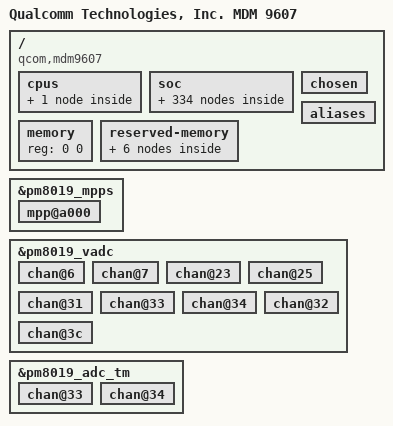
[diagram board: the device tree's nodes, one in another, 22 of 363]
/*
 * Copyright (c) 2015-2018, The Linux Foundation. All rights reserved.
 *
 * This program is free software; you can redistribute it and/or modify
 * it under the terms of the GNU General Public License version 2 and
 * only version 2 as published by the Free Software Foundation.
 *
 * This program is distributed in the hope that it will be useful,
 * but WITHOUT ANY WARRANTY; without even the implied warranty of
 * MERCHANTABILITY or FITNESS FOR A PARTICULAR PURPOSE.  See the
 * GNU General Public License for more details.
 */

// #include "skeleton.dtsi"
/*
 * Skeleton device tree; the bare minimum needed to boot; just include and
 * add a compatible value.  The bootloader will typically populate the memory
 * node.
 */

/ {
	#address-cells = <1>;
	#size-cells = <1>;
	cpus { };
	soc { };
	chosen { };
	aliases { };
	memory { device_type = "memory"; reg = <0 0>; };
};

#include <dt-bindings/clock/mdm-clocks-9607.h>
#include <dt-bindings/clock/msm-clocks-a7.h>
#include <dt-bindings/regulator/qcom,rpm-smd-regulator.h>
#include <dt-bindings/interrupt-controller/irq.h>

/ {
	model = "Qualcomm Technologies, Inc. MDM 9607";
	compatible = "qcom,mdm9607";
	qcom,msm-id = <290 0x10000>, <296 0x10000>, <297 0x10000>,
		      <298 0x10000>, <299 0x10000>;
	interrupt-parent = <&intc>;

	aliases {
		sdhc1 = &sdhc_1;/* SDC1 for SDIO slot */
		qpic_nand1 = &qnand_1;
	};

	reserved-memory {
		#address-cells = <1>;
		#size-cells = <1>;
		ranges;

		modem_adsp_mem: modem_adsp_region@0 {
			compatible = "removed-dma-pool";
			no-map-fixup;
			reg = <0x82c00000 0x5000000>;
		};

		cnss_debug_mem: cnss_debug_region@0 {
			compatible = "removed-dma-pool";
			no-map;
			reg = <0x82a00000 0x200000>;
		};

		external_image_mem: external_image_region@0 {
			compatible = "removed-dma-pool";
			no-map;
			reg = <0x87c00000 0x400000>;
		};

		tz_apps_mem: tz_apps_region@0 {
			compatible = "removed-dma-pool";
			no-map;
			reg = <0x88000000 0x500000>;
		};

		audio_mem: audio_region@0 {
			compatible = "shared-dma-pool";
			reusable;
			alignment = <0x400000>;
			size = <0x400000>;
		};

		qseecom_mem: qseecom_region@0 {
			compatible = "shared-dma-pool";
			reusable;
			alignment = <0x400000>;
			size = <0x0400000>;
			status = "ok";
		};
	};

	aliases {
		/* smdtty devices */
		smd7 = &smdtty_data1;
		smd8 = &smdtty_data4;
		smd9 = &smdtty_data2;
		smd10 = &smdtty_data3;
		/*smd11 = &smdtty_data11;*/ /*modified by max.tang@20160118. del Data11 from APP to be used by second USB AT port*/
		smd21 = &smdtty_data21;
		smd36 = &smdtty_loopback;
		/* spi device */
		/*Add spi3, spi5 node, gale 2018-3-14
		* according to AG35 Hardware Design, support three spi, spi_6 is actived,
		* and spi_3, spi_5 is inactived by default, user could enable it.
		*/
		spi3 = &spi_3;
		spi5 = &spi_5;
		//add by cullen
		spi6  = &spi_6;
		i2c2 = &i2c_2;
		i2c4 = &i2c_4;
		sdhc2 = &sdhc_2; /* SDC2 SD card slot */
	};

	cpus {
		#size-cells = <0>;
		#address-cells = <1>;

		CPU0: cpu@0 {
			device_type = "cpu";
			compatible = "arm,cortex-a7";
			reg = <0x0>;
			qcom,limits-info = <&mitigation_profile0>;
		};
	};
	soc: soc { };
};

// #include "mdm9607-ion.dtsi"
&soc {
	qcom,ion {
		compatible = "qcom,msm-ion";
		#address-cells = <1>;
		#size-cells = <0>;

		qcom,ion-heap@25 {
			reg = <25>;
			qcom,ion-heap-type = "SYSTEM";
		};

		qcom,ion-heap@28 { /* AUDIO HEAP */
			reg = <28>;
			memory-region = <&audio_mem>;
			qcom,ion-heap-type = "DMA";
		};

		qcom,ion-heap@27 { /* QSEECOM HEAP */
			reg = <27>;
			memory-region = <&qseecom_mem>;
			qcom,ion-heap-type = "DMA";
		};

	};
};

// #include "mdm9607-smp2p.dtsi"
&soc {
	qcom,smp2p-modem {
		compatible = "qcom,smp2p";
		reg = <0x0b011008 0x4>;
		qcom,remote-pid = <1>;
		qcom,irq-bitmask = <0x4000>;
		interrupts = <0 27 1>;
	};

	smp2pgpio_smp2p_15_in: qcom,smp2pgpio-smp2p-15-in {
		compatible = "qcom,smp2pgpio";
		qcom,entry-name = "smp2p";
		qcom,remote-pid = <15>;
		qcom,is-inbound;
		gpio-controller;
		#gpio-cells = <2>;
		interrupt-controller;
		#interrupt-cells = <2>;
	};

	qcom,smp2pgpio_test_smp2p_15_in {
		compatible = "qcom,smp2pgpio_test_smp2p_15_in";
		gpios = <&smp2pgpio_smp2p_15_in 0 0>;
	};

	smp2pgpio_smp2p_15_out: qcom,smp2pgpio-smp2p-15-out {
		compatible = "qcom,smp2pgpio";
		qcom,entry-name = "smp2p";
		qcom,remote-pid = <15>;
		gpio-controller;
		#gpio-cells = <2>;
		interrupt-controller;
		#interrupt-cells = <2>;
	};

	qcom,smp2pgpio_test_smp2p_15_out {
		compatible = "qcom,smp2pgpio_test_smp2p_15_out";
		gpios = <&smp2pgpio_smp2p_15_out 0 0>;
	};

	smp2pgpio_smp2p_1_in: qcom,smp2pgpio-smp2p-1-in {
		compatible = "qcom,smp2pgpio";
		qcom,entry-name = "smp2p";
		qcom,remote-pid = <1>;
		qcom,is-inbound;
		gpio-controller;
		#gpio-cells = <2>;
		interrupt-controller;
		#interrupt-cells = <2>;
	};

	qcom,smp2pgpio_test_smp2p_1_in {
		compatible = "qcom,smp2pgpio_test_smp2p_1_in";
		gpios = <&smp2pgpio_smp2p_1_in 0 0>;
	};

	smp2pgpio_smp2p_1_out: qcom,smp2pgpio-smp2p-1-out {
		compatible = "qcom,smp2pgpio";
		qcom,entry-name = "smp2p";
		qcom,remote-pid = <1>;
		gpio-controller;
		#gpio-cells = <2>;
		interrupt-controller;
		#interrupt-cells = <2>;
	};

	qcom,smp2pgpio_test_smp2p_1_out {
		compatible = "qcom,smp2pgpio_test_smp2p_1_out";
		gpios = <&smp2pgpio_smp2p_1_out 0 0>;
	};

	smp2pgpio_ssr_smp2p_1_in: qcom,smp2pgpio-ssr-smp2p-1-in {
			compatible = "qcom,smp2pgpio";
			qcom,entry-name = "slave-kernel";
			qcom,remote-pid = <1>;
			qcom,is-inbound;
			gpio-controller;
			#gpio-cells = <2>;
			interrupt-controller;
			#interrupt-cells = <2>;
	};

	smp2pgpio_ssr_smp2p_1_out: qcom,smp2pgpio-ssr-smp2p-1-out {
			compatible = "qcom,smp2pgpio";
			qcom,entry-name = "master-kernel";
			qcom,remote-pid = <1>;
			gpio-controller;
			#gpio-cells = <2>;
			interrupt-controller;
			#interrupt-cells = <2>;
	};
};


// #include "mdm9607-bus.dtsi"
#include <dt-bindings/msm/msm-bus-ids.h>
&soc {
	/* Version = 1 */
	ad_hoc_bus: ad-hoc-bus {
		compatible = "qcom,msm-bus-device";
		reg = <0x401000 0x58000>,
		      <0x500000 0x15080>;
		reg-names = "bimc-base", "pcnoc-base";

		/*Buses*/

		fab_bimc: fab-bimc {
			cell-id = <MSM_BUS_FAB_BIMC>;
			label = "fab-bimc";
			qcom,fab-dev;
			qcom,base-name = "bimc-base";
			qcom,bus-type = <2>;
			qcom,util-fact = <154>;
			clock-names = "bus_clk", "bus_a_clk";
			clocks = <&clock_gcc  clk_bimc_msmbus_clk>,
				<&clock_gcc  clk_bimc_msmbus_a_clk>;

			coresight-id = <203>;
			coresight-name = "coresight-bimc";
			coresight-nr-inports = <0>;
			coresight-outports = <0>;
			coresight-child-list = <&funnel_in0>;
			coresight-child-ports = <3>;
		};

		fab_pcnoc: fab-pcnoc {
			cell-id = <MSM_BUS_FAB_PERIPH_NOC>;
			label = "fab-pcnoc";
			qcom,fab-dev;
			qcom,base-name = "pcnoc-base";
			qcom,base-offset = <0x7000>;
			qcom,qos-off = <0x1000>;
			qcom,bus-type = <1>;
			clock-names = "bus_clk", "bus_a_clk";
			clocks = <&clock_gcc  clk_pcnoc_msmbus_clk>,
				<&clock_gcc  clk_pcnoc_msmbus_a_clk>;

			coresight-id = <201>;
			coresight-name = "coresight-pcnoc";
			coresight-nr-inports = <0>;
			coresight-outports = <0>;
			coresight-child-list = <&funnel_in2>;
			coresight-child-ports = <0>;
		};

		/*Masters*/

		mas_apps_proc: mas-apps-proc {
			cell-id = <MSM_BUS_MASTER_AMPSS_M0>;
			label = "mas-apps-proc";
			qcom,buswidth = <8>;
			qcom,agg-ports = <1>;
			qcom,ap-owned;
			qcom,qport = <0>;
			qcom,qos-mode = "fixed";
			qcom,connections = < &slv_bimc_pcnoc &slv_ebi>;
			qcom,prio-lvl = <0>;
			qcom,prio-rd = <0>;
			qcom,prio-wr = <0>;
			qcom,bus-dev = <&fab_bimc>;
			qcom,mas-rpm-id = <ICBID_MASTER_APPSS_PROC>;
		};

		mas_pcnoc_bimc_1: mas-pcnoc-bimc-1 {
			cell-id = <MSM_BUS_MASTER_PCNOC_BIMC_1>;
			label = "mas-pcnoc-bimc-1";
			qcom,buswidth = <8>;
			qcom,agg-ports = <1>;
			qcom,connections = <&slv_ebi>;
			qcom,bus-dev = <&fab_bimc>;
			qcom,mas-rpm-id = <ICBID_MASTER_PCNOC_BIMC_1>;
		};

		mas_tcu_0: mas-tcu-0 {
			cell-id = <MSM_BUS_MASTER_TCU_0>;
			label = "mas-tcu-0";
			qcom,buswidth = <8>;
			qcom,agg-ports = <1>;
			qcom,ap-owned;
			qcom,qport = <5>;
			qcom,qos-mode = "fixed";
			qcom,connections = <&slv_ebi>;
			qcom,prio-lvl = <2>;
			qcom,prio-rd = <2>;
			qcom,prio-wr = <2>;
			qcom,bus-dev = <&fab_bimc>;
			qcom,mas-rpm-id = <ICBID_MASTER_TCU_0>;
		};

		mas_qdss_bam: mas-qdss-bam {
			cell-id = <MSM_BUS_MASTER_QDSS_BAM>;
			label = "mas-qdss-bam";
			qcom,buswidth = <4>;
			qcom,agg-ports = <1>;
			qcom,connections = <&qdss_int>;
			qcom,bus-dev = <&fab_pcnoc>;
			qcom,mas-rpm-id = <ICBID_MASTER_QDSS_BAM>;
			qcom,blacklist = <&pcnoc_s_1 &pcnoc_s_2 &pcnoc_s_0
				 &pcnoc_s_4 &pcnoc_s_5 &pcnoc_s_3 &slv_tcu>;
		};

		mas_bimc_pcnoc: mas-bimc-pcnoc {
			cell-id = <MSM_BUS_MASTER_BIMC_PCNOC>;
			label = "mas-bimc-pcnoc";
			qcom,buswidth = <8>;
			qcom,agg-ports = <1>;
			qcom,connections = <&pcnoc_int_0
				 &pcnoc_int_2 &slv_cats_0>;
			qcom,bus-dev = <&fab_pcnoc>;
			qcom,mas-rpm-id = <ICBID_MASTER_BIMC_PCNOC>;
		};

		mas_qdss_etr: mas-qdss-etr {
			cell-id = <MSM_BUS_MASTER_QDSS_ETR>;
			label = "mas-qdss-etr";
			qcom,buswidth = <8>;
			qcom,agg-ports = <1>;
			qcom,connections = <&qdss_int>;
			qcom,bus-dev = <&fab_pcnoc>;
			qcom,mas-rpm-id = <ICBID_MASTER_QDSS_ETR>;
			qcom,blacklist = <&pcnoc_s_0 &pcnoc_s_2
					  &pcnoc_s_3 &pcnoc_s_4 &pcnoc_s_5
					  &slv_crypto_0_cfg &slv_message_ram
					  &slv_pdm &slv_prng &slv_qdss_stm
					  &slv_tcu>;
		};

		mas_audio: mas-audio {
			cell-id = <MSM_BUS_MASTER_AUDIO>;
			label = "mas-audio";
			qcom,buswidth = <4>;
			qcom,agg-ports = <1>;
			qcom,connections = <&pcnoc_m_0>;
			qcom,bus-dev = <&fab_pcnoc>;
			qcom,mas-rpm-id = <ICBID_MASTER_AUDIO>;
			qcom,blacklist = <&pcnoc_s_0 &pcnoc_s_1
					 &pcnoc_s_2 &pcnoc_s_3
					 &pcnoc_s_4 &pcnoc_s_5 &slv_tcu>;
		};

		mas_qpic: mas-qpic {
			cell-id = <MSM_BUS_MASTER_QPIC>;
			label = "mas-qpic";
			qcom,buswidth = <4>;
			qcom,agg-ports = <1>;
			qcom,connections = <&pcnoc_m_0>;
			qcom,bus-dev = <&fab_pcnoc>;
			qcom,mas-rpm-id = <ICBID_MASTER_QPIC>;
			qcom,blacklist = <&pcnoc_s_0 &pcnoc_s_2
					  &pcnoc_s_3 &pcnoc_s_4
					  &pcnoc_s_5 &slv_tcu
					  &slv_crypto_0_cfg &slv_pdm
					  &slv_prng &slv_usb2 >;
		};

		mas_hsic: mas-hsic {
			cell-id = <MSM_BUS_MASTER_USB_HSIC>;
			label = "mas-hsic";
			qcom,buswidth = <4>;
			qcom,agg-ports = <1>;
			qcom,connections = <&pcnoc_m_0>;
			qcom,bus-dev = <&fab_pcnoc>;
			qcom,mas-rpm-id = <ICBID_MASTER_USB_HSIC>;
		};

		mas_blsp_1: mas-blsp-1 {
			cell-id = <MSM_BUS_MASTER_BLSP_1>;
			label = "mas-blsp-1";
			qcom,buswidth = <4>;
			qcom,agg-ports = <1>;
			qcom,connections = <&pcnoc_m_1>;
			qcom,bus-dev = <&fab_pcnoc>;
			qcom,mas-rpm-id = <ICBID_MASTER_BLSP_1>;
			qcom,blacklist = <&pcnoc_s_0 &pcnoc_s_1
					 &pcnoc_s_2 &pcnoc_s_3
					 &pcnoc_s_4 &pcnoc_s_5 &slv_tcu >;
		};

		mas_usb_hs1: mas-usb-hs1 {
			cell-id = <MSM_BUS_MASTER_USB_HS>;
			label = "mas-usb-hs1";
			qcom,buswidth = <4>;
			qcom,agg-ports = <1>;
			qcom,connections = <&pcnoc_m_1>;
			qcom,bus-dev = <&fab_pcnoc>;
			qcom,mas-rpm-id = <ICBID_MASTER_USB_HS1>;
			qcom,blacklist = <&pcnoc_s_0 &pcnoc_s_2 &pcnoc_s_4
					 &pcnoc_s_5 &slv_tcu
					 &slv_crypto_0_cfg
					 &slv_pdm &slv_prng &slv_usb2
					 &slv_usb_phy> ;
		};

		mas_crypto: mas-crypto {
			cell-id = <MSM_BUS_MASTER_CRYPTO>;
			label = "mas-crypto";
			qcom,buswidth = <8>;
			qcom,agg-ports = <1>;
			qcom,ap-owned;
			qcom,qport = <0>;
			qcom,qos-mode = "fixed";
			qcom,connections = <&pcnoc_int_3>;
			qcom,prio1 = <2>;
			qcom,prio0 = <2>;
			qcom,bus-dev = <&fab_pcnoc>;
			qcom,mas-rpm-id = <ICBID_MASTER_CRYPTO>;
			qcom,blacklist = <&pcnoc_s_0 &pcnoc_s_2 &pcnoc_s_3
					  &pcnoc_s_4 &pcnoc_s_5 &slv_tcu
					  &slv_crypto_0_cfg &slv_pdm
					  &slv_usb2 &slv_prng>;
		};

		mas_sdcc_1: mas-sdcc-1 {
			cell-id = <MSM_BUS_MASTER_SDCC_1>;
			label = "mas-sdcc-1";
			qcom,buswidth = <8>;
			qcom,agg-ports = <1>;
			qcom,connections = <&pcnoc_int_3>;
			qcom,bus-dev = <&fab_pcnoc>;
			qcom,mas-rpm-id = <ICBID_MASTER_SDCC_1>;
			qcom,blacklist = <&pcnoc_s_0 &pcnoc_s_2 &pcnoc_s_3
					 &pcnoc_s_4 &pcnoc_s_5 &slv_tcu
					 &slv_crypto_0_cfg &slv_pdm
					 &slv_usb2 &slv_prng>;
		};

		mas_sdcc_2: mas-sdcc-2 {
			cell-id = <MSM_BUS_MASTER_SDCC_2>;
			label = "mas-sdcc-2";
			qcom,buswidth = <8>;
			qcom,agg-ports = <1>;
			qcom,connections = <&pcnoc_int_3>;
			qcom,bus-dev = <&fab_pcnoc>;
			qcom,mas-rpm-id = <ICBID_MASTER_SDCC_2>;
			qcom,blacklist = <&pcnoc_s_0 &pcnoc_s_2 &pcnoc_s_3
					 &pcnoc_s_4 &pcnoc_s_5 &slv_tcu
					 &slv_crypto_0_cfg &slv_pdm
					 &slv_usb2 &slv_prng>;
		};

		mas_xi_usb_hs1: mas-xi-usb-hs1 {
			cell-id = <MSM_BUS_MASTER_XM_USB_HS1>;
			label = "mas-xi-usb-hs1";
			qcom,buswidth = <8>;
			qcom,agg-ports = <1>;
			qcom,connections = <&slv_pcnoc_bimc_1 &pcnoc_int_2>;
			qcom,bus-dev = <&fab_pcnoc>;
			qcom,mas-rpm-id = <ICBID_MASTER_XI_USB_HS1>;
			qcom,blacklist = <&pcnoc_s_0 &pcnoc_s_2 &pcnoc_s_4
					 &pcnoc_s_5 &slv_tcu &slv_crypto_0_cfg
					 &slv_pdm &slv_usb2 &slv_prng
					 &slv_usb_phy>;
		};

		mas_xi_hsic: mas-xi-hsic {
			cell-id = <MSM_BUS_MASTER_XI_USB_HSIC>;
			label = "mas-xi-hsic";
			qcom,buswidth = <8>;
			qcom,agg-ports = <1>;
			qcom,connections = <&slv_pcnoc_bimc_1 &pcnoc_int_2>;
			qcom,bus-dev = <&fab_pcnoc>;
			qcom,mas-rpm-id = <ICBID_MASTER_XI_HSIC>;
			qcom,blacklist = <&pcnoc_s_0 &pcnoc_s_2
					 &pcnoc_s_3 &pcnoc_s_4 &pcnoc_s_5
					 &slv_tcu &slv_crypto_0_cfg
					 &slv_pdm &slv_usb2 &slv_prng>;
		};

		mas_sgmii: mas-sgmii {
			cell-id = <MSM_BUS_MASTER_SGMII>;
			label = "mas-sgmii";
			qcom,buswidth = <8>;
			qcom,agg-ports = <1>;
			qcom,ap-owned;
			qcom,qport = <10>;
			qcom,qos-mode = "fixed";
			qcom,connections = <&slv_pcnoc_bimc_1 &pcnoc_int_2>;
			qcom,prio1 = <1>;
			qcom,prio0 = <1>;
			qcom,bus-dev = <&fab_pcnoc>;
			qcom,mas-rpm-id = <ICBID_MASTER_SGMII>;
			qcom,blacklist = <&pcnoc_s_0 &pcnoc_s_2 &pcnoc_s_3
					 &pcnoc_s_4 &pcnoc_s_5 &slv_tcu
					 &slv_crypto_0_cfg &slv_pdm
					 &slv_usb2 &slv_prng>;
		};

		/*Internal nodes*/

		pcnoc_m_0: pcnoc-m-0 {
			cell-id = <MSM_BUS_PNOC_M_0>;
			label = "pcnoc-m-0";
			qcom,buswidth = <4>;
			qcom,agg-ports = <1>;
			qcom,connections = <&slv_pcnoc_bimc_1 &pcnoc_int_2>;
			qcom,bus-dev = <&fab_pcnoc>;
			qcom,mas-rpm-id = <ICBID_MASTER_PCNOC_M_0>;
			qcom,slv-rpm-id = <ICBID_SLAVE_PCNOC_M_0>;
		};

		pcnoc_m_1: pcnoc-m-1 {
			cell-id = <MSM_BUS_PNOC_M_1>;
			label = "pcnoc-m-1";
			qcom,buswidth = <4>;
			qcom,agg-ports = <1>;
			qcom,connections = <&slv_pcnoc_bimc_1 &pcnoc_int_2>;
			qcom,bus-dev = <&fab_pcnoc>;
			qcom,mas-rpm-id = <ICBID_MASTER_PCNOC_M_1>;
			qcom,slv-rpm-id = <ICBID_SLAVE_PCNOC_M_1>;
		};

		qdss_int: qdss-int {
			cell-id = <MSM_BUS_SNOC_QDSS_INT>;
			label = "qdss-int";
			qcom,buswidth = <8>;
			qcom,agg-ports = <1>;
			qcom,connections = <&pcnoc_int_0 &slv_pcnoc_bimc_1>;
			qcom,bus-dev = <&fab_pcnoc>;
			qcom,mas-rpm-id = <ICBID_MASTER_QDSS_INT>;
			qcom,slv-rpm-id = <ICBID_SLAVE_QDSS_INT>;
		};

		pcnoc_int_0: pcnoc-int-0 {
			cell-id = <MSM_BUS_PNOC_INT_0>;
			label = "pcnoc-int-0";
			qcom,buswidth = <8>;
			qcom,agg-ports = <1>;
			qcom,ap-owned;
			qcom,connections = <&slv_imem &slv_qdss_stm>;
			qcom,bus-dev = <&fab_pcnoc>;
			qcom,mas-rpm-id = <ICBID_MASTER_PCNOC_INT_0>;
			qcom,slv-rpm-id = <ICBID_SLAVE_PCNOC_INT_0>;
		};

		pcnoc_int_2: pcnoc-int-2 {
			cell-id = <MSM_BUS_PNOC_INT_2>;
			label = "pcnoc-int-2";
			qcom,buswidth = <8>;
			qcom,agg-ports = <1>;
			qcom,connections = <&pcnoc_s_1 &pcnoc_s_2
					 &pcnoc_s_0 &pcnoc_s_4
					 &pcnoc_s_5 &pcnoc_s_3
					 &slv_tcu >;
			qcom,bus-dev = <&fab_pcnoc>;
			qcom,mas-rpm-id = <ICBID_MASTER_PCNOC_INT_2>;
			qcom,slv-rpm-id = <ICBID_SLAVE_PCNOC_INT_2>;
		};

		pcnoc_int_3: pcnoc-int-3 {
			cell-id = <MSM_BUS_PNOC_INT_3>;
			label = "pcnoc-int-3";
			qcom,buswidth = <8>;
			qcom,agg-ports = <1>;
			qcom,connections = <&slv_pcnoc_bimc_1 &pcnoc_int_2>;
			qcom,bus-dev = <&fab_pcnoc>;
			qcom,mas-rpm-id = <ICBID_MASTER_PCNOC_INT_3>;
			qcom,slv-rpm-id = <ICBID_SLAVE_PCNOC_INT_3>;
		};

		pcnoc_s_0: pcnoc-s-0 {
			cell-id = <MSM_BUS_PNOC_SLV_0>;
			label = "pcnoc-s-0";
			qcom,buswidth = <4>;
			qcom,agg-ports = <1>;
			qcom,connections = <&slv_tcsr &slv_sdcc_1 &slv_blsp_1
				 &slv_sgmii>;
			qcom,bus-dev = <&fab_pcnoc>;
			qcom,mas-rpm-id = <ICBID_MASTER_PCNOC_S_0>;
			qcom,slv-rpm-id = <ICBID_SLAVE_PCNOC_S_0>;
		};

		pcnoc_s_1: pcnoc-s-1 {
			cell-id = <MSM_BUS_PNOC_SLV_1>;
			label = "pcnoc-s-1";
			qcom,buswidth = <4>;
			qcom,agg-ports = <1>;
			qcom,connections = <&slv_usb2 &slv_crypto_0_cfg
					 &slv_prng &slv_pdm
					 &slv_message_ram>;
			qcom,bus-dev = <&fab_pcnoc>;
			qcom,mas-rpm-id = <ICBID_MASTER_PCNOC_S_1>;
			qcom,slv-rpm-id = <ICBID_SLAVE_PCNOC_S_1>;
		};

		pcnoc_s_2: pcnoc-s-2 {
			cell-id = <MSM_BUS_PNOC_SLV_2>;
			label = "pcnoc-s-2";
			qcom,buswidth = <4>;
			qcom,agg-ports = <1>;
			qcom,connections = <&slv_hsic &slv_sdcc_2 &slv_audio>;
			qcom,bus-dev = <&fab_pcnoc>;
			qcom,mas-rpm-id = <ICBID_MASTER_PCNOC_S_2>;
			qcom,slv-rpm-id = <ICBID_SLAVE_PCNOC_S_2>;
		};

		pcnoc_s_3: pcnoc-s-3 {
			cell-id = <MSM_BUS_PNOC_SLV_3>;
			label = "pcnoc-s-3";
			qcom,buswidth = <4>;
			qcom,agg-ports = <1>;
			qcom,ap-owned;
			qcom,connections = <&slv_usb_phy>;
			qcom,bus-dev = <&fab_pcnoc>;
			qcom,mas-rpm-id = <ICBID_MASTER_PCNOC_S_3>;
			qcom,slv-rpm-id = <ICBID_SLAVE_PCNOC_S_3>;
		};

		pcnoc_s_4: pcnoc-s-4 {
			cell-id = <MSM_BUS_PNOC_SLV_4>;
			label = "pcnoc-s-4";
			qcom,buswidth = <4>;
			qcom,agg-ports = <1>;
			qcom,connections = <&slv_imem_cfg &slv_pmic_arb>;
			qcom,bus-dev = <&fab_pcnoc>;
			qcom,mas-rpm-id = <ICBID_MASTER_PCNOC_S_4>;
			qcom,slv-rpm-id = <ICBID_SLAVE_PCNOC_S_4>;
		};

		pcnoc_s_5: pcnoc-s-5 {
			cell-id = <MSM_BUS_PNOC_SLV_5>;
			label = "pcnoc-s-5";
			qcom,buswidth = <4>;
			qcom,agg-ports = <1>;
			qcom,connections = <&slv_tlmm>;
			qcom,bus-dev = <&fab_pcnoc>;
			qcom,mas-rpm-id = <ICBID_MASTER_PCNOC_S_5>;
			qcom,slv-rpm-id = <ICBID_SLAVE_PCNOC_S_5>;
		};

		/*Slaves*/

		slv_ebi:slv-ebi {
			cell-id = <MSM_BUS_SLAVE_EBI_CH0>;
			label = "slv-ebi";
			qcom,buswidth = <8>;
			qcom,agg-ports = <1>;
			qcom,bus-dev = <&fab_bimc>;
			qcom,slv-rpm-id = <ICBID_SLAVE_EBI1>;
		};

		slv_bimc_pcnoc:slv-bimc-pcnoc {
			cell-id = <MSM_BUS_SLAVE_BIMC_PCNOC>;
			label = "slv-bimc-pcnoc";
			qcom,buswidth = <8>;
			qcom,agg-ports = <1>;
			qcom,bus-dev = <&fab_bimc>;
			qcom,connections = <&mas_bimc_pcnoc>;
			qcom,slv-rpm-id = <ICBID_SLAVE_BIMC_PCNOC>;
		};

		slv_pcnoc_bimc_1:slv-pcnoc-bimc-1 {
			cell-id = <MSM_BUS_SLAVE_PCNOC_BIMC_1>;
			label = "slv-pcnoc-bimc-1";
			qcom,buswidth = <8>;
			qcom,agg-ports = <1>;
			qcom,bus-dev = <&fab_pcnoc>;
			qcom,connections = <&mas_pcnoc_bimc_1>;
			qcom,slv-rpm-id = <ICBID_SLAVE_PCNOC_BIMC_1>;
		};

		slv_qdss_stm:slv-qdss-stm {
			cell-id = <MSM_BUS_SLAVE_QDSS_STM>;
			label = "slv-qdss-stm";
			qcom,buswidth = <4>;
			qcom,agg-ports = <1>;
			qcom,ap-owned;
			qcom,bus-dev = <&fab_pcnoc>;
			qcom,slv-rpm-id = <ICBID_SLAVE_QDSS_STM>;
		};

		slv_cats_0:slv-cats-0 {
			cell-id = <MSM_BUS_SLAVE_CATS_128>;
			label = "slv-cats-0";
			qcom,buswidth = <8>;
			qcom,agg-ports = <1>;
			qcom,ap-owned;
			qcom,bus-dev = <&fab_pcnoc>;
			qcom,slv-rpm-id = <ICBID_SLAVE_CATS_0>;
		};

		slv_imem:slv-imem {
			cell-id = <MSM_BUS_SLAVE_SYSTEM_IMEM>;
			label = "slv-imem";
			qcom,buswidth = <8>;
			qcom,agg-ports = <1>;
			qcom,ap-owned;
			qcom,bus-dev = <&fab_pcnoc>;
			qcom,slv-rpm-id = <ICBID_SLAVE_IMEM>;
		};

		slv_tcsr:slv-tcsr {
			cell-id = <MSM_BUS_SLAVE_TCSR>;
			label = "slv-tcsr";
			qcom,buswidth = <4>;
			qcom,agg-ports = <1>;
			qcom,bus-dev = <&fab_pcnoc>;
			qcom,slv-rpm-id = <ICBID_SLAVE_TCSR>;
		};

		slv_sdcc_1:slv-sdcc-1 {
			cell-id = <MSM_BUS_SLAVE_SDCC_1>;
			label = "slv-sdcc-1";
			qcom,buswidth = <4>;
			qcom,agg-ports = <1>;
			qcom,bus-dev = <&fab_pcnoc>;
			qcom,slv-rpm-id = <ICBID_SLAVE_SDCC_1>;
		};

		slv_blsp_1:slv-blsp-1 {
			cell-id = <MSM_BUS_SLAVE_BLSP_1>;
			label = "slv-blsp-1";
			qcom,buswidth = <4>;
			qcom,agg-ports = <1>;
			qcom,bus-dev = <&fab_pcnoc>;
			qcom,slv-rpm-id = <ICBID_SLAVE_BLSP_1>;
		};

		slv_sgmii:slv-sgmii {
			cell-id = <MSM_BUS_SLAVE_SGMII>;
			label = "slv-sgmii";
			qcom,buswidth = <4>;
			qcom,agg-ports = <1>;
			qcom,ap-owned;
			qcom,bus-dev = <&fab_pcnoc>;
			qcom,slv-rpm-id = <ICBID_SLAVE_SGMII>;
		};

		slv_crypto_0_cfg:slv-crypto-0-cfg {
			cell-id = <MSM_BUS_SLAVE_CRYPTO_0_CFG>;
			label = "slv-crypto-0-cfg";
			qcom,buswidth = <4>;
			qcom,agg-ports = <1>;
			qcom,ap-owned;
			qcom,bus-dev = <&fab_pcnoc>;
			qcom,slv-rpm-id = <ICBID_SLAVE_CRYPTO_0_CFG>;
		};

		slv_message_ram:slv-message-ram {
			cell-id = <MSM_BUS_SLAVE_MESSAGE_RAM>;
			label = "slv-message-ram";
			qcom,buswidth = <4>;
			qcom,agg-ports = <1>;
			qcom,bus-dev = <&fab_pcnoc>;
			qcom,slv-rpm-id = <ICBID_SLAVE_MESSAGE_RAM>;
		};

		slv_pdm:slv-pdm {
			cell-id = <MSM_BUS_SLAVE_PDM>;
			label = "slv-pdm";
			qcom,buswidth = <4>;
			qcom,agg-ports = <1>;
			qcom,bus-dev = <&fab_pcnoc>;
			qcom,slv-rpm-id = <ICBID_SLAVE_PDM>;
		};

		slv_prng:slv-prng {
			cell-id = <MSM_BUS_SLAVE_PRNG>;
			label = "slv-prng";
			qcom,buswidth = <4>;
			qcom,agg-ports = <1>;
			qcom,bus-dev = <&fab_pcnoc>;
			qcom,slv-rpm-id = <ICBID_SLAVE_PRNG>;
		};

		slv_usb2:slv-usb2 {
			cell-id = <MSM_BUS_SLAVE_USB_HS>;
			label = "slv-usb2";
			qcom,buswidth = <4>;
			qcom,agg-ports = <1>;
			qcom,ap-owned;
			qcom,bus-dev = <&fab_pcnoc>;
			qcom,slv-rpm-id = <ICBID_SLAVE_USB_HS>;
		};

		slv_sdcc_2:slv-sdcc-2 {
			cell-id = <MSM_BUS_SLAVE_SDCC_2>;
			label = "slv-sdcc-2";
			qcom,buswidth = <4>;
			qcom,agg-ports = <1>;
			qcom,bus-dev = <&fab_pcnoc>;
			qcom,slv-rpm-id = <ICBID_SLAVE_SDCC_2>;
		};

		slv_audio:slv-audio {
			cell-id = <MSM_BUS_SLAVE_AUDIO>;
			label = "slv-audio";
			qcom,buswidth = <4>;
			qcom,agg-ports = <1>;
			qcom,bus-dev = <&fab_pcnoc>;
			qcom,slv-rpm-id = <ICBID_SLAVE_AUDIO>;
		};

		slv_hsic:slv-hsic {
			cell-id = <MSM_BUS_SLAVE_USB_HSIC>;
			label = "slv-hsic";
			qcom,buswidth = <4>;
			qcom,agg-ports = <1>;
			qcom,bus-dev = <&fab_pcnoc>;
			qcom,slv-rpm-id = <ICBID_SLAVE_USB_HSIC>;
		};

		slv_usb_phy:slv-usb-phy {
			cell-id = <MSM_BUS_SLAVE_USB_PHYS_CFG>;
			label = "slv-usb-phy";
			qcom,buswidth = <4>;
			qcom,agg-ports = <1>;
			qcom,ap-owned;
			qcom,bus-dev = <&fab_pcnoc>;
			qcom,slv-rpm-id = <ICBID_SLAVE_USB_PHY_CFG>;
		};

		slv_tlmm:slv-tlmm {
			cell-id = <MSM_BUS_SLAVE_TLMM>;
			label = "slv-tlmm";
			qcom,buswidth = <4>;
			qcom,agg-ports = <1>;
			qcom,bus-dev = <&fab_pcnoc>;
			qcom,slv-rpm-id = <ICBID_SLAVE_TLMM>;
		};

		slv_imem_cfg:slv-imem-cfg {
			cell-id = <MSM_BUS_SLAVE_IMEM_CFG>;
			label = "slv-imem-cfg";
			qcom,buswidth = <4>;
			qcom,agg-ports = <1>;
			qcom,ap-owned;
			qcom,bus-dev = <&fab_pcnoc>;
			qcom,slv-rpm-id = <ICBID_SLAVE_IMEM_CFG>;
		};

		slv_pmic_arb:slv-pmic-arb {
			cell-id = <MSM_BUS_SLAVE_PMIC_ARB>;
			label = "slv-pmic-arb";
			qcom,buswidth = <4>;
			qcom,agg-ports = <1>;
			qcom,bus-dev = <&fab_pcnoc>;
			qcom,slv-rpm-id = <ICBID_SLAVE_PMIC_ARB>;
		};

		slv_tcu:slv-tcu {
			cell-id = <MSM_BUS_SLAVE_TCU>;
			label = "slv-tcu";
			qcom,buswidth = <8>;
			qcom,agg-ports = <1>;
			qcom,ap-owned;
			qcom,bus-dev = <&fab_pcnoc>;
			qcom,slv-rpm-id = <ICBID_SLAVE_TCU>;
		};

		slv_qipc {
			cell-id = <MSM_BUS_SLAVE_QPIC>;
			label = "slv-qpic";
			qcom,buswidth = <4>;
			qcom,agg-ports = <1>;
			qcom,bus-dev = <&fab_pcnoc>;
			qcom,slv-rpm-id = <ICBID_SLAVE_QPIC>;

		};
	};
};

// #include "mdm9607-coresight.dtsi"

&soc {
	tmc_etr: tmc@6026000 {
		compatible = "arm,coresight-tmc";
		reg = <0x6026000 0x1000>,
		      <0x6084000 0x15000>;
		reg-names = "tmc-base", "bam-base";
		interrupts = <0 166 0>;
		interrupt-names = "byte-cntr-irq";

		qcom,memory-size = <0x100000>;
		qcom,sg-enable;

		coresight-id = <0>;
		coresight-name = "coresight-tmc-etr";
		coresight-nr-inports = <1>;
		coresight-ctis = <&cti0 &cti8>;

		clocks = <&clock_gcc clk_qdss_clk>,
			 <&clock_gcc clk_qdss_a_clk>;
		clock-names = "core_clk", "core_a_clk";
	};

	tpiu: tpiu@6020000 {
		compatible = "arm,coresight-tpiu";
		reg = <0x6020000 0x1000>,
		      <0x1100000 0xb0000>;
		reg-names = "tpiu-base", "nidnt-base";

		coresight-id = <1>;
		coresight-name = "coresight-tpiu";
		coresight-nr-inports = <1>;

		pinctrl-names = "sdcard", "trace", "swduart",
				"swdtrc", "jtag", "spmi";
		/* NIDnT */
		pinctrl-0 = <&qdsd_clk_sdcard &qdsd_cmd_sdcard
			     &qdsd_data0_sdcard &qdsd_data1_sdcard
			     &qdsd_data2_sdcard &qdsd_data3_sdcard>;
		pinctrl-1 = <&qdsd_clk_trace &qdsd_cmd_trace
			     &qdsd_data0_trace &qdsd_data1_trace
			     &qdsd_data2_trace &qdsd_data3_trace>;
		pinctrl-2 = <&qdsd_cmd_swduart &qdsd_data0_swduart
			     &qdsd_data1_swduart &qdsd_data2_swduart
			     &qdsd_data3_swduart>;
		pinctrl-3 = <&qdsd_clk_swdtrc &qdsd_cmd_swdtrc
			     &qdsd_data0_swdtrc &qdsd_data1_swdtrc
			     &qdsd_data2_swdtrc &qdsd_data3_swdtrc>;
		pinctrl-4 = <&qdsd_cmd_jtag &qdsd_data0_jtag
			     &qdsd_data1_jtag &qdsd_data2_jtag
			     &qdsd_data3_jtag>;
		pinctrl-5 = <&qdsd_clk_spmi &qdsd_cmd_spmi
			     &qdsd_data0_spmi &qdsd_data3_spmi>;

		qcom,nidnthw;
		qcom,nidnt-swduart;
		qcom,nidnt-swdtrc;
		qcom,nidnt-jtag;
		qcom,nidnt-spmi;
		nidnt-gpio = <&tlmm_pinmux 26 0>;
		nidnt-gpio-polarity = <1>;

		interrupts = <0 82 0>;
		interrupt-names = "nidnt-irq";

		vdd-supply = <&sdcard_ext_vreg>;
		qcom,vdd-voltage-level = <2850000 2850000>;
		qcom,vdd-current-level = <15 400000>;

		vdd-io-supply = <&mdm9607_l13>;
		qcom,vdd-io-voltage-level = <1800000 2950000>;
		qcom,vdd-io-current-level = <200 300000>;

		clocks = <&clock_gcc clk_qdss_clk>,
			 <&clock_gcc clk_qdss_a_clk>;
		clock-names = "core_clk", "core_a_clk";
	};

	replicator: replicator@6024000 {
		compatible = "qcom,coresight-replicator";
		reg = <0x6024000 0x1000>;
		reg-names = "replicator-base";

		coresight-id = <2>;
		coresight-name = "coresight-replicator";
		coresight-nr-inports = <1>;
		coresight-outports = <0 1>;
		coresight-child-list = <&tmc_etr &tpiu>;
		coresight-child-ports = <0 0>;

		clocks = <&clock_gcc clk_qdss_clk>,
			 <&clock_gcc clk_qdss_a_clk>;
		clock-names = "core_clk", "core_a_clk";
	};

	tmc_etf: tmc@6025000 {
		compatible = "arm,coresight-tmc";
		reg = <0x6025000 0x1000>;
		reg-names = "tmc-base";

		coresight-id = <3>;
		coresight-name = "coresight-tmc-etf";
		coresight-nr-inports = <1>;
		coresight-outports = <0>;
		coresight-child-list = <&replicator>;
		coresight-child-ports = <0>;
		coresight-default-sink;
		coresight-ctis = <&cti0 &cti8>;

		clocks = <&clock_gcc clk_qdss_clk>,
			 <&clock_gcc clk_qdss_a_clk>;
		clock-names = "core_clk", "core_a_clk";
	};

	funnel_in0: funnel@6021000 {
		compatible = "arm,coresight-funnel";
		reg = <0x6021000 0x1000>;
		reg-names = "funnel-base";

		coresight-id = <4>;
		coresight-name = "coresight-funnel-in0";
		coresight-nr-inports = <8>;
		coresight-outports = <0>;
		coresight-child-list = <&tmc_etf>;
		coresight-child-ports = <0>;

		clocks = <&clock_gcc clk_qdss_clk>,
			 <&clock_gcc clk_qdss_a_clk>;
		clock-names = "core_clk", "core_a_clk";
	};

	funnel_in2: funnel@6068000 {
		compatible = "arm,coresight-funnel";
		reg = <0x6068000 0x1000>;
		reg-names = "funnel-base";

		coresight-id = <5>;
		coresight-name = "coresight-funnel-in2";
		coresight-nr-inports = <2>;
		coresight-outports = <0>;
		coresight-child-list = <&funnel_in0>;
		coresight-child-ports = <6>;

		clocks = <&clock_gcc clk_qdss_clk>,
			 <&clock_gcc clk_qdss_a_clk>;
		clock-names = "core_clk", "core_a_clk";
	};

	cti0: cti@6010000 {
		compatible = "arm,coresight-cti";
		reg = <0x6010000 0x1000>;
		reg-names = "cti-base";

		coresight-id = <6>;
		coresight-name = "coresight-cti0";
		coresight-nr-inports = <0>;

		clocks = <&clock_gcc clk_qdss_clk>,
			 <&clock_gcc clk_qdss_a_clk>;
		clock-names = "core_clk", "core_a_clk";
	};

	cti1: cti@6011000 {
		compatible = "arm,coresight-cti";
		reg = <0x6011000 0x1000>;
		reg-names = "cti-base";

		coresight-id = <7>;
		coresight-name = "coresight-cti1";
		coresight-nr-inports = <0>;

		clocks = <&clock_gcc clk_qdss_clk>,
			 <&clock_gcc clk_qdss_a_clk>;
		clock-names = "core_clk", "core_a_clk";
	};

	cti2: cti@6012000 {
		compatible = "arm,coresight-cti";
		reg = <0x6012000 0x1000>;
		reg-names = "cti-base";

		coresight-id = <8>;
		coresight-name = "coresight-cti2";
		coresight-nr-inports = <0>;

		clocks = <&clock_gcc clk_qdss_clk>,
			 <&clock_gcc clk_qdss_a_clk>;
		clock-names = "core_clk", "core_a_clk";
	};

	cti3: cti@6013000 {
		compatible = "arm,coresight-cti";
		reg = <0x6013000 0x1000>;
		reg-names = "cti-base";

		coresight-id = <9>;
		coresight-name = "coresight-cti3";
		coresight-nr-inports = <0>;

		clocks = <&clock_gcc clk_qdss_clk>,
			 <&clock_gcc clk_qdss_a_clk>;
		clock-names = "core_clk", "core_a_clk";
	};

	cti4: cti@6014000 {
		compatible = "arm,coresight-cti";
		reg = <0x6014000 0x1000>;
		reg-names = "cti-base";

		coresight-id = <10>;
		coresight-name = "coresight-cti4";
		coresight-nr-inports = <0>;

		clocks = <&clock_gcc clk_qdss_clk>,
			 <&clock_gcc clk_qdss_a_clk>;
		clock-names = "core_clk", "core_a_clk";
	};

	cti5: cti@6015000 {
		compatible = "arm,coresight-cti";
		reg = <0x6015000 0x1000>;
		reg-names = "cti-base";

		coresight-id = <11>;
		coresight-name = "coresight-cti5";
		coresight-nr-inports = <0>;

		clocks = <&clock_gcc clk_qdss_clk>,
			 <&clock_gcc clk_qdss_a_clk>;
		clock-names = "core_clk", "core_a_clk";
	};

	cti6: cti@6016000 {
		compatible = "arm,coresight-cti";
		reg = <0x6016000 0x1000>;
		reg-names = "cti-base";

		coresight-id = <12>;
		coresight-name = "coresight-cti6";
		coresight-nr-inports = <0>;

		clocks = <&clock_gcc clk_qdss_clk>,
			 <&clock_gcc clk_qdss_a_clk>;
		clock-names = "core_clk", "core_a_clk";
	};

	cti7: cti@6017000 {
		compatible = "arm,coresight-cti";
		reg = <0x6017000 0x1000>;
		reg-names = "cti-base";

		coresight-id = <13>;
		coresight-name = "coresight-cti7";
		coresight-nr-inports = <0>;

		clocks = <&clock_gcc clk_qdss_clk>,
			 <&clock_gcc clk_qdss_a_clk>;
		clock-names = "core_clk", "core_a_clk";
	};

	cti8: cti@6018000 {
		compatible = "arm,coresight-cti";
		reg = <0x6018000 0x1000>;
		reg-names = "cti-base";

		coresight-id = <14>;
		coresight-name = "coresight-cti8";
		coresight-nr-inports = <0>;

		clocks = <&clock_gcc clk_qdss_clk>,
			 <&clock_gcc clk_qdss_a_clk>;
		clock-names = "core_clk", "core_a_clk";
	};

	cti_cpu0: cti@6043000 {
		compatible = "arm,coresight-cti";
		reg = <0x6043000 0x1000>;
		reg-names = "cti-base";

		coresight-id = <15>;
		coresight-name = "coresight-cti-cpu0";
		coresight-nr-inports = <0>;
		coresight-cti-cpu = <&CPU0>;

		qcom,cti-save;

		clocks = <&clock_gcc clk_qdss_clk>,
			 <&clock_gcc clk_qdss_a_clk>;
		clock-names = "core_clk", "core_a_clk";
	};

	cti_rpm_cpu0: cti@603c000 {
		compatible = "arm,coresight-cti";
		reg = <0x603c000 0x1000>;
		reg-names = "cti-base";

		coresight-id = <16>;
		coresight-name = "coresight-cti-rpm-cpu0";
		coresight-nr-inports = <0>;

		clocks = <&clock_gcc clk_qdss_clk>,
			 <&clock_gcc clk_qdss_a_clk>;
		clock-names = "core_clk", "core_a_clk";
	};

	cti_modem_cpu0: cti@6038000 {
		compatible = "arm,coresight-cti";
		reg = <0x6038000 0x1000>;
		reg-names = "cti-base";

		coresight-id = <17>;
		coresight-name = "coresight-cti-modem-cpu0";
		coresight-nr-inports = <0>;

		clocks = <&clock_gcc clk_qdss_clk>,
			 <&clock_gcc clk_qdss_a_clk>;
		clock-names = "core_clk", "core_a_clk";
	};

	stm: stm@6002000 {
		compatible = "arm,coresight-stm";
		reg = <0x6002000 0x1000>,
		      <0x9280000 0x180000>;
		reg-names = "stm-base", "stm-data-base";

		coresight-id = <18>;
		coresight-name = "coresight-stm";
		coresight-nr-inports = <0>;
		coresight-outports = <0>;
		coresight-child-list = <&funnel_in0>;
		coresight-child-ports = <7>;

		clocks = <&clock_gcc clk_qdss_clk>,
			 <&clock_gcc clk_qdss_a_clk>;
		clock-names = "core_clk", "core_a_clk";
	};

	csr: csr@6001000 {
		compatible = "qcom,coresight-csr";
		reg = <0x6001000 0x1000>;
		reg-names = "csr-base";

		coresight-id = <19>;
		coresight-name = "coresight-csr";
		coresight-nr-inports = <0>;

		qcom,blk-size = <1>;

		clocks = <&clock_gcc clk_qdss_clk>,
			 <&clock_gcc clk_qdss_a_clk>;
		clock-names = "core_clk", "core_a_clk";
	};

	etm0: etm@6042000 {
		compatible = "arm,coresight-etm";
		reg = <0x6042000 0x1000>;
		reg-names = "etm-base";

		coresight-id = <20>;
		coresight-name = "coresight-etm0";
		coresight-nr-inports = <0>;
		coresight-outports = <0>;
		coresight-child-list = <&funnel_in0>;
		coresight-child-ports = <4>;
		coresight-etm-cpu = <&CPU0>;

		clocks = <&clock_gcc clk_qdss_clk>,
			 <&clock_gcc clk_qdss_a_clk>;
		clock-names = "core_clk", "core_a_clk";
	};

	hwevent: hwevent@606c000 {
		compatible = "qcom,coresight-hwevent";
		reg = <0x606c000 0x148>,
		      <0x606cfb0 0x4>,
		      <0x78640cc 0x4>,
		      <0x78240cc 0x4>,
		      <0x7885010 0x4>,
		      <0x200c004 0x4>,
		      <0x78d90a0 0x4>;
		reg-names = "wrapper-mux", "wrapper-lockaccess",
			    "wrapper-sdcc2", "wrapper-sdcc1",
			    "blsp-mux", "spmi-mux" ,"usb-mux";

		coresight-id = <21>;
		coresight-name = "coresight-hwevent";
		coresight-nr-inports = <0>;

		clocks = <&clock_gcc clk_qdss_clk>,
			 <&clock_gcc clk_qdss_a_clk>;
		clock-names = "core_clk", "core_a_clk";
	};

	rpm_etm0 {
		compatible = "qcom,coresight-remote-etm";

		coresight-id = <22>;
		coresight-name = "coresight-rpm-etm0";
		coresight-nr-inports = <0>;
		coresight-outports = <0>;
		coresight-child-list = <&funnel_in0>;
		coresight-child-ports = <0>;

		qcom,inst-id = <4>;
	};

	modem_etm0 {
		compatible = "qcom,coresight-remote-etm";

		coresight-id = <23>;
		coresight-name = "coresight-modem-etm0";
		coresight-nr-inports = <0>;
		coresight-outports = <0>;
		coresight-child-list = <&funnel_in0>;
		coresight-child-ports = <2>;

		qcom,inst-id = <2>;
	};

	fuse: fuse@a601c {
		compatible = "arm,coresight-fuse-v2";
		reg = <0xa601c 0x8>;
		reg-names = "fuse-base";

		coresight-id = <24>;
		coresight-name = "coresight-fuse";
		coresight-nr-inports = <0>;
	};

	dbgui: dbgui@606d000 {
		compatible = "qcom,coresight-dbgui";
		reg = <0x606d000 0x1000>;
		reg-names = "dbgui-base";

		coresight-id = <25>;
		coresight-name = "coresight-dbgui";
		coresight-nr-inports = <0>;
		coresight-outports = <0>;
		coresight-child-list = <&funnel_in2>;
		coresight-child-ports = <1>;

		qcom,dbgui-addr-offset = <0x30>;
		qcom,dbgui-data-offset = <0xB0>;
		qcom,dbgui-size = <32>;

		clocks = <&clock_gcc clk_qdss_clk>,
			 <&clock_gcc clk_qdss_a_clk>;
		clock-names = "core_clk", "core_a_clk";
	};
};

// #include "mdm9607-pm.dtsi"
#include <dt-bindings/msm/pm.h>
&soc {
	qcom,spm@b009000 {
		compatible = "qcom,spm-v2";
		#address-cells = <1>;
		#size-cells = <1>;
		reg = <0xb009000 0x1000>;
		qcom,name = "cpu0";
		qcom,cpu = <&CPU0>;
		qcom,saw2-ver-reg = <0xfd0>;
		qcom,saw2-cfg = <0x1>;
		qcom,saw2-spm-dly= <0x3c102800>;
		qcom,saw2-spm-ctl = <0xe>;
		qcom,mode0 {
			qcom,label = "qcom,saw2-spm-cmd-wfi";
			qcom,sequence = [04 03 04 0f];
			qcom,spm_en;
		};
		qcom,mode1 {
			qcom,label = "qcom,saw2-spm-cmd-spc";
			qcom,sequence = [1f 34 04 44 24 54 03
				54 44 04 24 34 0f];
			qcom,spm_en;
			qcom,pc_mode;
		};
		qcom,mode2 {
			qcom,label = "qcom,saw2-spm-cmd-pc";
			qcom,sequence = [1f 34 04 44 14 24 54 03
				54 44 14 04 04 24 04 34 0f];
			qcom,spm_en;
			qcom,pc_mode;
			qcom,slp_cmd_mode;
		};
	};

	qcom,lpm-levels {
		compatible = "qcom,lpm-levels";
		#address-cells = <1>;
		#size-cells = <0>;

		qcom,pm-cluster@0{
			#address-cells = <1>;
			#size-cells = <0>;
			reg = <0>;
			label = "system";
			qcom,default-level=<0>;

			qcom,pm-cluster-level@0 {
				reg = <0>;
				label = "l2-active";
				qcom,latency-us = <270>;
				qcom,ss-power = <455>;
				qcom,energy-overhead = <270621>;
				qcom,time-overhead = <500>;
			};

			qcom,pm-cluster-level@1 {
				reg = <1>;
				label = "l2-pc";
				qcom,latency-us = <285>;
				qcom,ss-power = <442>;
				qcom,energy-overhead = <306621>;
				qcom,time-overhead = <540>;
				qcom,min-child-idx = <2>;
				qcom,notify-rpm;
				qcom,reset-level = <LPM_RESET_LVL_PC>;
			};

			qcom,pm-cpu {
				#address-cells = <1>;
				#size-cells = <0>;

				qcom,pm-cpu-level@0{
					reg = <0>;
					qcom,spm-cpu-mode = "wfi";
					qcom,latency-us = <1>;
					qcom,ss-power = <473>;
					qcom,energy-overhead = <100000>;
					qcom,time-overhead = <25>;
				};

				qcom,pm-cpu-level@1 {
					reg = <1>;
					qcom,spm-cpu-mode ="standalone_pc";
					qcom,latency-us = <240>;
					qcom,ss-power = <467>;
					qcom,energy-overhead = <202781>;
					qcom,time-overhead = <420>;
					qcom,use-broadcast-timer;
					qcom,is-reset;
					qcom,reset-level = <LPM_RESET_LVL_PC>;
				};

				qcom,pm-cpu-level@2 {
					reg = <2>;
					qcom,spm-cpu-mode = "pc";
					qcom,latency-us = <270>;
					qcom,ss-power = <455>;
					qcom,energy-overhead = <270621>;
					qcom,time-overhead = <500>;
					qcom,use-broadcast-timer;
					qcom,is-reset;
					qcom,reset-level = <LPM_RESET_LVL_PC>;
				};
			};
		};
	};

	qcom,mpm@601d0 {
		compatible = "qcom,mpm-v2";
		reg = <0x601d0 0x1000>, /* MSM_RPM_MPM_BASE 4K */
		    <0xb011008 0x4>;
		reg-names = "vmpm", "ipc";
		interrupts = <0 171 1>;
		clocks = <&clock_gcc clk_xo_lpm_clk>;
		clock-names = "xo";
		qcom,ipc-bit-offset = <1>;
		qcom,gic-parent = <&intc>;
		qcom,gic-map = <2 216>, /* tsens_upper_lower_int */
			<49 172>, /* usb1_hs_async_wakeup_irq */
			<51 174>, /* usb2_hs_async_wakeup_irq */
			<53 104>, /* mdss_irq */
			<58 166>, /* usb_hs_irq */
			<62 222>, /* ee0_apps_hlos_spmi_periph_irq */
			<0xff 18>,  /* WDT_biteInt */
			<0xff 19>,  /* WDT_barkInt */
			<0xff 35>,  /* CTI_SPI_intx */
			<0xff 38>,  /* QTMR_qgicFrm0VirtIrq */
			<0xff 47>,
			<0xff 56>,  /* q6_wdog_expired_irq */
			<0xff 57>,  /* mss_to_apps_irq(0) */
			<0xff 58>,  /* mss_to_apps_irq(1) */
			<0xff 59>,  /* mss_to_apps_irq(2) */
			<0xff 60>,  /* mss_to_apps_irq(3) */
			<0xff 61>,  /* mss_a2_bam_irq */
			<0xff 77>,  /* qpic_bam_irq[1] */
			<0xff 114>, /* qdsd_intr_out */
			<0xff 130>, /* peripheral_irq[9] */
			<0xff 131>, /* qup_irq */
			<0xff 140>, /* uart_dm_intr */
			<0xff 153>, /* peripheral_irq[4] */
			<0xff 155>, /* sdc1_irq(0) */
			<0xff 157>, /* sdc2_irq(0) */
			<0xff 161>, /* qpic_nandc_op_done_irq */
			<0xff 163>, /* qpic_lcdc_irq */
			<0xff 164>, /* qpic_bam_irq[0] */
			<0xff 168>,
			<0xff 170>, /* sdc1_pwr_cmd_irq */
			<0xff 173>, /* hsic_core_irq */
			<0xff 192>, /* audio_out0_irq */
			<0xff 198>, /* qdss_etrbytecnt_irq */
			<0xff 200>, /* rpm_ipc(4) */
			<0xff 201>, /* rpm_ipc(5) */
			<0xff 202>, /* rpm_ipc(6) */
			<0xff 203>, /* rpm_ipc(7) */
			<0xff 204>, /* rpm_ipc(24) */
			<0xff 205>, /* rpm_ipc(25) */
			<0xff 206>, /* rpm_ipc(26) */
			<0xff 207>, /* rpm_ipc(27) */
			<0xff 208>, /* rbif_irq[0] */
			<0xff 215>, /* o_bimc_intr */
			<0xff 224>, /* spdm_realtime_irq(1) */
			<0xff 239>, /* crypto_bam_irq[1]*/
			<0xff 240>, /* summary_irq_kpss */
			<0xff 244>, /* bam_irq[2] */
			<0xff 253>, /* sdc2_pwr_cmd_irq */
			<0xff 269>, /* rpm_wdog_expired_irq */
			<0xff 270>, /* bam_irq[0] */
			<0xff 275>, /* rpm_ipc(30) */
			<0xff 276>; /* rpm_ipc(31) */

		qcom,gpio-parent = <&tlmm_pinmux>;
		qcom,gpio-map = <3  16>,
			<4  5>,
			<5  11>,
			<6  12>,
			<7  3>,
			<8  17>,
			<9  9>,
			<10  13>,
			<11  1>,
			<12  20>,
			<13  21>,
			<14  22>,
			<15  75>,
			<16  74>,
			<17  28>,
			<18  44>,
			<19  26>,
			<20  43>,
			<21  42>,
			<22  29>,
			<23  69>,
			<24  30>,
			<25  37>,
			<26  25>,
			<27  71>,
			<28  34>,
			<29  55>,
			<30  8>,
			<31  40>,
			<32  48>,
			<33  52>,
			<34  57>,
			<35  62>,
			<36  66>,
			<37  59>,
			<38  79>,
			<39  38>,
			<40  63>,
			<41  76>;
	};

	qcom,pm@8600664 {
		compatible = "qcom,pm";
		reg = <0x8600664 0x40>;
		clocks = <&clock_cpu  clk_a7ssmux>;
		clock-names = "cpu0_clk";
		qcom,use-sync-timer;
		qcom,synced-clocks;
		qcom,tz-flushes-cache;
	};

	qcom,cpu-sleep-status@b088008{
		compatible = "qcom,cpu-sleep-status";
		reg = <0xb088008 0x100>;
		qcom,cpu-alias-addr = <0x10000>;
		qcom,sleep-status-mask= <0x80000>;
	};

	qcom,rpm-log@29dc00 {
		compatible = "qcom,rpm-log";
		reg = <0x29dc00 0x4000>;
		qcom,rpm-addr-phys = <0x200000>;
		qcom,offset-version = <4>;
		qcom,offset-page-buffer-addr = <36>;
		qcom,offset-log-len = <40>;
		qcom,offset-log-len-mask = <44>;
		qcom,offset-page-indices = <56>;
	};

	qcom,rpm-stats@29dba0 {
		compatible = "qcom,rpm-stats";
		reg = <0x29dba0 0x1000>;
		reg-names = "phys_addr_base";
		qcom,sleep-stats-version = <2>;
	};

	qcom,rpm-master-stats@60150 {
		compatible = "qcom,rpm-master-stats";
		reg = <0x60150 0x2030>;
		qcom,masters = "APSS", "MPSS", "PRONTO";
		qcom,master-stats-version = <2>;
		qcom,master-offset = <4096>;
	};

	qcom,rpm-rbcpr-stats@200000 {
		compatible = "qcom,rpmrbcpr-stats";
		reg = <0x200000 0x1000>;
		qcom,start-offset = <0x90010>;
	};
};

&soc {
	#address-cells = <1>;
	#size-cells = <1>;
	ranges;

	intc: interrupt-controller@b000000 {
		compatible = "qcom,msm-qgic2";
		interrupt-controller;
		#interrupt-cells = <3>;
		reg = <0x0b000000 0x1000>,
		      <0x0b002000 0x1000>;
	};

	qcom,mpm2-sleep-counter@4a3000 {
		compatible = "qcom,mpm2-sleep-counter";
		reg = <0x4a3000 0x1000>;
		clock-frequency = <32768>;
	};

	//net_status: use linux kernel leds-gpio method, gale 2017-11-11
	leds_gpio {
		compatible = "gpio-leds";
		net_status{
			gpios = <&pm8019_gpios 1 0>;
			default-state = "off";
			status = "disabled";
		};
	};

	timer@b020000 {
		#address-cells = <1>;
		#size-cells = <1>;
		ranges;
		compatible = "arm,armv7-timer-mem";
		reg = <0xb020000 0x1000>;
		clock-frequency = <19200000>;

		frame@b021000 {
			frame-number = <0>;
			interrupts = <0 7 0x4>,
				     <0 6 0x4>;
			reg = <0xb021000 0x1000>,
			      <0xb022000 0x1000>;
		};

		frame@b023000 {
			frame-number = <1>;
			interrupts = <0 8 0x4>;
			reg = <0xb023000 0x1000>;
			status = "disabled";
		};

		frame@b024000 {
			frame-number = <2>;
			interrupts = <0 9 0x4>;
			reg = <0xb024000 0x1000>;
			status = "disabled";
		};

		frame@b025000 {
			frame-number = <3>;
			interrupts = <0 10 0x4>;
			reg = <0xb025000 0x1000>;
			status = "disabled";
		};

		frame@b026000 {
			frame-number = <4>;
			interrupts = <0 11 0x4>;
			reg = <0xb026000 0x1000>;
			status = "disabled";
		};

		frame@b027000 {
			frame-number = <5>;
			interrupts = <0 12 0x4>;
			reg = <0xb027000 0x1000>;
			status = "disabled";
		};

		frame@b028000 {
			frame-number = <6>;
			interrupts = <0 13 0x4>;
			reg = <0xb028000 0x1000>;
			status = "disabled";
		};

		frame@b029000 {
			frame-number = <7>;
			interrupts = <0 14 0x4>;
			reg = <0xb029000 0x1000>;
			status = "disabled";
		};
	};

	qcom,wdt@b017000 {
		compatible = "qcom,msm-watchdog";
		reg = <0xb017000 0x1000>;
		reg-names = "wdt-base";
		interrupts = <0 3 0>, <0 4 0>;
		qcom,bark-time = <11000>;
		qcom,pet-time = <10000>;
		qcom,wakeup-enable;
	};

	qcom,msm-rtb {
		compatible = "qcom,msm-rtb";
		qcom,rtb-size = <0x10000>; /* 64K EBI1 buffer */
	};

	qcom,msm-imem@8600000 {
		compatible = "qcom,msm-imem";
		reg = <0x08600000 0x1000>; /* Address and size of IMEM */
		ranges = <0x0 0x08600000 0x1000>;
		#address-cells = <1>;
		#size-cells = <1>;

		mem_dump_table@10 {
			compatible = "qcom,msm-imem-mem_dump_table";
			reg = <0x10 8>;
		};

		restart_reason@65c {
			compatible = "qcom,msm-imem-restart_reason";
			reg = <0x65c 4>;
		};

		boot_stats@6b0 {
			compatible = "qcom,msm-imem-boot_stats";
			reg = <0x6b0 32>;
		};

		pil@94c {
			compatible = "qcom,msm-imem-pil";
			reg = <0x94c 200>;
		};
	};

	restart@4ab000 {
		compatible = "qcom,pshold";
		reg = <0x4ab000 0x4>,
		      <0x193d100 0x4>;
		      reg-names = "pshold-base", "tcsr-boot-misc-detect";
	};

	jtag_fuse: jtagfuse@a601c {
		compatible = "qcom,jtag-fuse-v2";
		reg = <0xa601c 0x8>;
		reg-names = "fuse-base";
	};

	jtag_mm: jtagmm@6042000 {
		compatible = "qcom,jtagv8-mm";
		reg = <0x6042000 0x1000>,
		      <0x6040000 0x1000>;
		reg-names = "etm-base", "debug-base";

		clocks = <&clock_gcc clk_qdss_clk>,
			 <&clock_gcc clk_qdss_a_clk>;
		clock-names = "core_clk", "core_a_clk";

		qcom,coresight-jtagmm-cpu = <&CPU0>;
	};

	clock_gcc: qcom,gcc@1800000 {
		compatible = "qcom,gcc-mdm9607";
		reg = <0x1800000 0x80000>,
			<0x0b008000 0x00050>;
		reg-names = "cc_base", "apcs_base";
		vdd_dig-supply = <&mdm9607_s3_level>;
		vdd_stromer_dig-supply = <&mdm9607_s3_level_ao>;
		#clock-cells = <1>;
	};

	clock_debug: qcom,debug@1874000 {
		compatible = "qcom,cc-debug-mdm9607";
		reg = <0x1800000 0x80000>,
			<0xb01101c 0x8>;
		reg-names = "cc_base", "meas";
		#clock-cells = <1>;
	};

	clock_cpu: qcom,clock-a7@10008 {
		compatible = "qcom,clock-a7-mdm9607";
		reg = <0x0b010008 0x8>,
				<0x000a412c 0x8>;
		reg-names = "rcg-base", "efuse";
		qcom,safe-freq = < 400000000 >;
		cpu-vdd-supply = <&apc_vreg_corner>;
		clocks = <&clock_gcc clk_gpll0_ao_clk_src>,
					<&clock_gcc clk_a7sspll>;
		clock-names = "clk-1", "clk-5";
		qcom,speed4-bin-v0 =
				<          0 0>,
				<  400000000 1>,
				<  800000000 2>,
				<  998400000 3>,
				< 1094400000 4>,
				< 1190400000 5>,
				< 1248000000 6>,
				< 1305600000 7>;
		qcom,a7ssmux-opp-store-vcorner = <&CPU0>;
		#clock-cells = <1>;
	};

	cpubw: qcom,cpubw {
		compatible = "qcom,devbw";
		governor = "cpufreq";
		qcom,src-dst-ports = <1 512>;
		qcom,active-only;
		qcom,bw-tbl =
			<  366 /*  48   MHz */>,
			<  732 /*  96   MHz */>,
			<  915 /* 120   MHz */>,
			< 1145 /* 150.15 MHz */>,
			< 1831 /* 240   MHz */>,
			< 2291 /* 300.3 MHZ */>;
	};

	devfreq-cpufreq {
		cpubw-cpufreq {
			target-dev = <&cpubw>;
			cpu-to-dev-map =
				 <  400000   732>,
				 <  800000   915>,
				 <  998400  1145>,
				 < 1094400  1831>,
				 < 1305600  2291>;
		};
	};

	qcom,cpu-bwmon {
		compatible = "qcom,bimc-bwmon2";
		reg = <0x408000 0x300>, <0x401000 0x200>;
		reg-names = "base", "global_base";
		interrupts = <0 183 4>;
		qcom,mport = <0>;
		qcom,target-dev = <&cpubw>;
	};

	qcom,msm-cpufreq {
		reg = <0 4>;
		compatible = "qcom,msm-cpufreq";
		clocks = <&clock_cpu  clk_a7ssmux>;
		clock-names = "cpu0_clk";
		qcom,cpufreq-table =
				<  400000 >,
				<  800000 >,
				<  998400 >,
				< 1094400 >,
				< 1190400 >,
				< 1248000 >,
				< 1305600 >;
	};

	qcom,sps {
		compatible = "qcom,msm_sps_4k";
		qcom,pipe-attr-ee;
	};

	/* BLSP1 UART2 gpio4,5: debug uart*/
	blsp1_uart2: serial@78b0000 { 
		compatible = "qcom,msm-lsuart-v14";
		reg = <0x78b0000 0x200>;
		interrupts = <0 108 0>;
		clocks = <&clock_gcc clk_gcc_blsp1_uart2_apps_clk>,
			 <&clock_gcc clk_gcc_blsp1_ahb_clk>;
		clock-names = "core_clk", "iface_clk";
		pinctrl-names = "default","sleep";
		pinctrl-0 = <&blsp1_uart2_active>;
		pinctrl-1 = <&blsp1_uart2_sleep>;
		status = "disabled";
	};

	/* BLSP1 UART5 gpio8,9 */
	blsp1_uart5: serial@78b3000 {
		compatible = "qcom,msm-lsuart-v14";
		reg = <0x78b3000 0x200>;
		interrupts = <0 121 0>;
		clocks = <&clock_gcc clk_gcc_blsp1_uart5_apps_clk>,
			 <&clock_gcc clk_gcc_blsp1_ahb_clk>;
		clock-names = "core_clk", "iface_clk";
		pinctrl-names = "sleep", "default";
		pinctrl-0 = <&uart_console_sleep>;
		pinctrl-1 = <&uart_console_active>;
		status = "disabled";
	};

	/* BLSP1 UART6  gpio20,21,22,23 */
	blsp1_uart6: serial@78b4000 {
		compatible = "qcom,msm-lsuart-v14";
		reg = <0x78b4000 0x200>;
		interrupts = <0 122 0>;			
		qcom,master-id = <86>;
		clock-names = "core_clk", "iface_clk";
		clocks = <&clock_gcc clk_gcc_blsp1_uart6_apps_clk>,
				<&clock_gcc clk_gcc_blsp1_ahb_clk>;
		pinctrl-names = "sleep", "default";
		pinctrl-0 = <&blsp1_uart6_sleep>;
		pinctrl-1 = <&blsp1_uart6_active>;
		qcom,msm-bus,name = "blsp1_uart6";
		qcom,msm-bus,num-cases = <2>;
		qcom,msm-bus,num-paths = <1>;
		qcom,msm-bus,vectors-KBps =
				<86 512 0 0>,
				<86 512 500 800>;
		status = "disabled";
	};


	/* BLSP1 UART3: gpio0,1,2,3: main uart*/
	blsp1_uart3: uart@78b1000 {
		compatible = "qcom,msm-hsuart-v14";
		reg = <0x78b1000 0x200>,
			<0x7884000 0x2b000>;
		reg-names = "core_mem", "bam_mem";
		//interrupt-names = "core_irq", "bam_irq", "wakeup_irq"; //disable uart rx wakeup source
		interrupt-names = "core_irq", "bam_irq";
		#address-cells = <0>;
		interrupt-parent = <&blsp1_uart3>;
		//interrupts = <0 1 2>; 			//disable uart rx wakeup source
		interrupts = <0 1>;
		#interrupt-cells = <1>;
		interrupt-map-mask = <0xffffffff>;
		interrupt-map = <0 &intc 0 119 0
				1 &intc 0 238 0>;
				//2 &tlmm_pinmux 1 0>; 	//disable uart rx wakeup source

		//qcom,inject-rx-on-wakeup; 	//disable uart rx wakeup source
		//qcom,rx-char-to-inject = <0xFD>;	//disable uart rx wakeup source


		qcom,bam-tx-ep-pipe-index = <4>;
		qcom,bam-rx-ep-pipe-index = <5>;
		qcom,master-id = <86>;
		clock-names = "core_clk", "iface_clk";
		clocks = <&clock_gcc clk_gcc_blsp1_uart3_apps_clk>,
				<&clock_gcc clk_gcc_blsp1_ahb_clk>;
		pinctrl-names = "sleep", "default";
		pinctrl-0 = <&blsp1_uart3_sleep>;
		pinctrl-1 = <&blsp1_uart3_active>;
		qcom,msm-bus,name = "blsp1_uart3";
		qcom,msm-bus,num-cases = <2>;
		qcom,msm-bus,num-paths = <1>;
		qcom,msm-bus,vectors-KBps =
				<86 512 0 0>,
				<86 512 500 800>;
		status = "disabled";
	};

	/* BLSP1 UART5 gpio8,9,10,11, high speed mode */
	blsp1_uart5_hs: uart@78b3000 {
		compatible = "qcom,msm-hsuart-v14";
		reg = <0x78b3000 0x200>,
			<0x7884000 0x23000>;
		reg-names = "core_mem", "bam_mem";
		interrupt-names = "core_irq", "bam_irq", "wakeup_irq";
		#address-cells = <0>;
		interrupt-parent = <&blsp1_uart5_hs>;
		interrupts = <0 1 2>;
		#interrupt-cells = <1>;
		interrupt-map-mask = <0xffffffff>;
		interrupt-map = <0 &intc 0 121 0
				1 &intc 0 238 0
				2 &tlmm_pinmux 9 0>;

		qcom,inject-rx-on-wakeup;
		qcom,rx-char-to-inject = <0xFD>;

		qcom,bam-tx-ep-pipe-index = <8>;
		qcom,bam-rx-ep-pipe-index = <9>;
		qcom,master-id = <86>;
		clock-names = "core_clk", "iface_clk";
		clocks = <&clock_gcc clk_gcc_blsp1_uart5_apps_clk>,
			<&clock_gcc clk_gcc_blsp1_ahb_clk>;
		pinctrl-names = "sleep", "default";
		pinctrl-0 = <&blsp1_uart5_sleep>;
		pinctrl-1 = <&blsp1_uart5_active>;

		qcom,msm-bus,name = "buart5";
		qcom,msm-bus,num-cases = <2>;
		qcom,msm-bus,num-paths = <1>;
		qcom,msm-bus,vectors-KBps =
				<86 512 0 0>,
				<86 512 500 800>;
		status = "disabled";
	};
	
	dma_blsp1: qcom,sps-dma@7884000 { /* BLSP1 */
		#dma-cells = <4>;
		compatible = "qcom,sps-dma";
		reg = <0x7884000 0x2b000>;
		interrupts = <0 238 0>;
		qcom,summing-threshold = <10>;
	};

	i2c_2: i2c@78b6000 { /* BLSP2*/
		compatible = "qcom,i2c-msm-v2";
		#address-cells = <1>;
		#size-cells = <0>;
		reg-names = "qup_phys_addr";
		reg = <0x78b6000 0x600>;
		interrupt-names = "qup_irq";
		interrupts = <0 96 0>;
		qcom,clk-freq-out = <400000>;
		qcom,clk-freq-in  = <19200000>;
		clock-names = "iface_clk", "core_clk";
		clocks = <&clock_gcc clk_gcc_blsp1_ahb_clk>,
			<&clock_gcc clk_gcc_blsp1_qup2_i2c_apps_clk>;

		pinctrl-names = "i2c_active", "i2c_sleep";
		pinctrl-0 = <&i2c_2_active>;
		pinctrl-1 = <&i2c_2_sleep>;
		qcom,noise-rjct-scl = <0>;
		qcom,noise-rjct-sda = <0>;
		qcom,master-id = <86>;
		dmas = <&dma_blsp1 14 32 0x20000020 0x20>,
			<&dma_blsp1 15 64 0x20000020 0x20>;
		dma-names = "tx", "rx";
		status = "disabled";
                /*add by javen:2018-11-19*/
		bmi160@68{
			compatible = "bosch-sensortec,bmi160";
			reg = <0x68>;
			pinctrl-names = "default";
			pinctrl-0 = <&sensor_int1_default &sensor_int2_default>;
			interrupt-parent = <&tlmm_pinmux>;
			interrupts = <38 0x2002>;
			bmi,init-interval = <200>;
			bmi,place = <1>;
			bmi,gpio_irq = <&tlmm_pinmux 38 0x2002>;
			status = "disabled"; 
		};
//2019-01-12:javen-increase smi130 config 
		smi130_gyro@69{
			compatible = "smi130_gyro";
			reg = <0x69>;
			interrupt-parent = <&tlmm_pinmux>;
			interrupts = <42 0x2002>;
			smi130_gyro,gpio_irq = <&tlmm_pinmux 42 0x2002>;
			status = "ok"; 
		};
		smi130_acc@19{
			compatible = "smi130_acc";
			reg = <0x19>;
			interrupt-parent = <&tlmm_pinmux>;
			interrupts = <74 0x2002>;
			smi130_acc,gpio_irq = <&tlmm_pinmux 74 0x2002>;
			status = "ok"; 
		};
};

	i2c_4: i2c@78b8000 { /* BLSP1 QUP4 */
		compatible = "qcom,i2c-msm-v2";
		#address-cells = <1>;
		#size-cells = <0>;
		reg-names = "qup_phys_addr";
		reg = <0x78b8000 0x600>;
		interrupt-names = "qup_irq";
		interrupts = <0 98 0>;
		qcom,clk-freq-out = <400000>;
		qcom,clk-freq-in  = <19200000>;
		clock-names = "iface_clk", "core_clk";
		clocks = <&clock_gcc clk_gcc_blsp1_ahb_clk>,
			<&clock_gcc clk_gcc_blsp1_qup4_i2c_apps_clk>;

		pinctrl-names = "i2c_active", "i2c_sleep";
		pinctrl-0 = <&i2c_4_active>;
		pinctrl-1 = <&i2c_4_sleep>;
		qcom,noise-rjct-scl = <0>;
		qcom,noise-rjct-sda = <0>;
		qcom,master-id = <86>;
		dmas = <&dma_blsp1 18 64 0x20000020 0x20>,
			<&dma_blsp1 19 32 0x20000020 0x20>;
		dma-names = "tx", "rx";
		status = "disabled";

		/* achang-20180622, add codec dts settings */
		max9867_codec: max9867@19{
			compatible = "maxim,max9867";
			reg = <0x19>;//reg = <0x18>;
		};

		rt5616_codec: rt5616@1b{
			compatible = "realtek,rt5616";
			reg = <0x1b>;
		};

		nau8810_codec: nau8810@1a{
			compatible = "nuvoton,nau8810";
			reg = <0x1a>;
		};

		tlv320aic3x_codec: tlv320aic3x@18{
			compatible = "ti,tlv320aic3104";
			reg = <0x18>;
			ai3x-ocmv = <0>;
			ai3x-micbias-vg = <2>;
		};

		wcd9xxx_tomtom_codec@d{
			compatible = "qcom,wcd9xxx-i2c";
			reg = <0x0d>;
			status = "disabled"; /* achang-20180622, not use */

			qcom,cdc-reset-gpio = <&tlmm_pinmux 26 0>;
			pinctrl-names = "default", "idle";
			pinctrl-0 = <&codec_reset_active>;
			pinctrl-1 = <&codec_reset_sleep>;

			qcom,cdc-micbias1-ext-cap;

			interrupt-parent = <&wcd9xxx_intc>;
			interrupts = <0 1 2 3 4 5 6 7 8 9 10 11 12 13 14 15
				16 17 18 19 20 21 22 23 24 25 26 27 28>;
			cdc-vdd-buck-supply = <&mdm9607_s4>;
			qcom,cdc-vdd-buck-voltage = <1950000 1950000>;
			qcom,cdc-vdd-buck-current = <25000>;

			cdc-vdd-tx-h-supply = <&mdm9607_l11>;
			qcom,cdc-vdd-tx-h-voltage = <1800000 1800000>;
			qcom,cdc-vdd-tx-h-current = <25000>;

			cdc-vdd-rx-h-supply = <&mdm9607_l11>;
			qcom,cdc-vdd-rx-h-voltage = <1800000 1800000>;
			qcom,cdc-vdd-rx-h-current = <25000>;

			cdc-vddpx-1-supply = <&mdm9607_l11>;
			qcom,cdc-vddpx-1-voltage = <1800000 1800000>;
			qcom,cdc-vddpx-1-current = <10000>;

			cdc-vdd-a-1p2v-supply = <&mdm9607_l9>;
			qcom,cdc-vdd-a-1p2v-voltage = <1225000 1225000>;
			qcom,cdc-vdd-a-1p2v-current = <10000>;

			cdc-vddcx-1-supply = <&mdm9607_l9>;
			qcom,cdc-vddcx-1-voltage = <1225000 1225000>;
			qcom,cdc-vddcx-1-current = <10000>;

			cdc-vddcx-2-supply = <&mdm9607_l9>;
			qcom,cdc-vddcx-2-voltage = <1225000 1225000>;
			qcom,cdc-vddcx-2-current = <10000>;

			qcom,cdc-static-supplies = "cdc-vdd-buck",
						   "cdc-vdd-tx-h",
						   "cdc-vdd-rx-h",
						   "cdc-vddpx-1",
						   "cdc-vdd-a-1p2v",
						   "cdc-vddcx-1",
						   "cdc-vddcx-2";

			qcom,cdc-micbias-ldoh-v = <0x3>;
			qcom,cdc-micbias-cfilt1-mv = <1800>;
			qcom,cdc-micbias-cfilt2-mv = <2700>;
			qcom,cdc-micbias-cfilt3-mv = <1800>;
			qcom,cdc-micbias1-cfilt-sel = <0x0>;
			qcom,cdc-micbias2-cfilt-sel = <0x1>;
			qcom,cdc-micbias3-cfilt-sel = <0x2>;
			qcom,cdc-micbias4-cfilt-sel = <0x2>;
			qcom,cdc-mclk-clk-rate = <12288000>;
			qcom,cdc-dmic-sample-rate = <4800000>;
			qcom,cdc-variant = "WCD9330";
		};

		wcd9xxx_tapan_codec@d{
			compatible = "qcom,wcd9xxx-i2c";
			reg = <0x0d>;

			status = "disabled";
			qcom,cdc-reset-gpio = <&tlmm_pinmux 26 0>;
			pinctrl-names = "default", "idle";
			pinctrl-0 = <&codec_reset_active>;
			pinctrl-1 = <&codec_reset_sleep>;

			qcom,cdc-micbias1-ext-cap;

			interrupt-parent = <&wcd9xxx_intc>;
			interrupts = <0 1 2 3 4 5 6>, <7 8 9 10 11 12 13>,
					<14 15 16 17 18 19 20>,
					<21 22 23 24 25 26 27 28>;
			cdc-vdd-buck-supply = <&mdm9607_s4>;
			qcom,cdc-vdd-buck-voltage = <1950000 1950000>;
			qcom,cdc-vdd-buck-current = <25000>;

			cdc-vdd-tx-h-supply = <&mdm9607_l11>;
			qcom,cdc-vdd-tx-h-voltage = <1800000 1800000>;
			qcom,cdc-vdd-tx-h-current = <25000>;

			cdc-vdd-rx-h-supply = <&mdm9607_l11>;
			qcom,cdc-vdd-rx-h-voltage = <1800000 1800000>;
			qcom,cdc-vdd-rx-h-current = <25000>;

			cdc-vddpx-1-supply = <&mdm9607_l11>;
			qcom,cdc-vddpx-1-voltage = <1800000 1800000>;
			qcom,cdc-vddpx-1-current = <10000>;

			cdc-vdd-cx-supply = <&mdm9607_l9>;
			qcom,cdc-vdd-cx-voltage = <1225000 1225000>;
			qcom,cdc-vdd-cx-current = <10000>;

			qcom,cdc-static-supplies = "cdc-vdd-buck",
						   "cdc-vdd-tx-h",
						   "cdc-vdd-rx-h",
						   "cdc-vddpx-1",
						   "cdc-vdd-cx";

			qcom,cdc-micbias-ldoh-v = <0x3>;
			qcom,cdc-micbias-cfilt1-mv = <1800>;
			qcom,cdc-micbias-cfilt2-mv = <2700>;
			qcom,cdc-micbias-cfilt3-mv = <1800>;
			qcom,cdc-micbias1-cfilt-sel = <0x0>;
			qcom,cdc-micbias2-cfilt-sel = <0x1>;
			qcom,cdc-micbias3-cfilt-sel = <0x2>;
			qcom,cdc-micbias4-cfilt-sel = <0x2>;
			qcom,cdc-mclk-clk-rate = <12288000>;
			qcom,cdc-dmic-sample-rate = <4800000>;
			qcom,cdc-variant = "WCD9306";
		};

		wcd9xxx_codec@77{
			compatible = "qcom,wcd9xxx-i2c";
			reg = <0x77>;
			status = "disabled"; /* achang-20180622, not use */
		};

		wcd9xxx_codec@66{
			compatible = "qcom,wcd9xxx-i2c";
			reg = <0x66>;
			status = "disabled"; /* achang-20180622, not use */
		};

		wcd9xxx_codec@55{
			compatible = "qcom,wcd9xxx-i2c";
			reg = <0x55>;
			status = "disabled"; /* achang-20180622, not use */
		};

		iam20680@69{
			compatible = "inven,iam20680";
			reg = <0x69>;
			pinctrl-names = "default";
			pinctrl-0 = <&sensor_int1_default &sensor_int2_default>;
			interrupt-parent = <&tlmm_pinmux>;
			interrupts = <78 IRQ_TYPE_EDGE_RISING>;
			axis_map_x = <1>;
			axis_map_y = <0>;
			axis_map_z = <2>;
			negate_x = <1>;
			negate_y = <0>;
			negate_z = <0>;
			inven,secondary_type = "none";
			inven,aux_type = "none";
			inven,read_only_slave_type = "none";
		};

		asm330@6b{
			compatible = "st,asm330lhh";
			reg = <0x6b>;
			pinctrl-names = "default";
			pinctrl-0 = <&sensor_int1_default &sensor_int2_default>;
			interrupt-parent = <&tlmm_pinmux>;
			interrupts = <78 IRQ_TYPE_EDGE_RISING>;
		};

	};

	cnss_sdio: qcom,cnss-sdio {
		compatible = "qcom,cnss_sdio";
		reg = <0x82a00000 0x200000>;
		reg-names = "ramdump";
		subsys-name = "AR6320";
		/* To enable PIN PM_ENABLE_WIFI dynamicly in dbgfs /sys/kernel/debug/regulator/rome_vreg, gale 2018-04-01 */
		/*vdd-wlan-supply = <&rome_vreg>;*/
		/* Disable sdcard_ext_vreg, refer to quectel STATUS pin, gale 2018-04-01*/
		/*vdd-wlan-dsrc-supply = <&sdcard_ext_vreg>;*/
		vdd-wlan-io-supply = <&mdm9607_l11>;
		vdd-wlan-xtal-supply = <&mdm9607_l2>;
	};

	usb_otg: usb@78d9000 {
		compatible = "qcom,hsusb-otg";
		reg = <0x78d9000 0x400>, <0x6c000 0x200>;
		reg-names = "core", "phy_csr";
		#address-cells = <1>;
		#size-cells = <1>;
		ranges;

		interrupts = <0 134 0>, <0 140 0>;
		interrupt-names = "core_irq", "async_irq";

		hsusb_vdd_dig-supply = <&mdm9607_l9>;
		HSUSB_1p8-supply = <&mdm9607_l2>;
		HSUSB_3p3-supply = <&mdm9607_l4>;
		qcom,vdd-voltage-level = <0 1225000 1225000>;

		qcom,hsusb-otg-phy-init-seq =
			<0x44 0x80 0x38 0x81 0x24 0x82 0x13 0x83 0xffffffff>;

		qcom,hsusb-otg-phy-type = <3>; /* SNPS Femto PHY */
		qcom,hsusb-otg-mode = <1>; /* peripheral mode ivan 20160104 change 3-->1 solved the USB not working problem*/
                qcom,hsusb-otg-default-mode=<1>; /* peripheral mode ivan 20160104 add  solved the USB not working problem*/
		qcom,hsusb-otg-otg-control = <3>; /* USR control ivan 20160104 change 2-->3 solved the USB not working problem*/
		qcom,usbid-gpio = <&pm8019_mpps 1 0>;
		qcom,hsusb-log2-itc = <4>;
		qcom,dp-manual-pullup;
		qcom,boost-sysclk-with-streaming;
		qcom,phy-dvdd-always-on;
		qcom,hsusb-otg-lpm-on-dev-suspend;
		qcom,axi-prefetch-enable;
		qcom,hsusb-otg-mpm-dpsehv-int = <49>;
		qcom,hsusb-otg-mpm-dmsehv-int = <58>;
		qcom,hsusb-otg-delay-lpm;
		qcom,enable-phy-id-pullup;

		qcom,msm-bus,name = "usb2";
		qcom,msm-bus,num-cases = <3>;
		qcom,msm-bus,num-paths = <1>;
		qcom,msm-bus,vectors-KBps =
				<87 512 0 0>,
				<87 512 80000 0>,
				<87 512 6000  6000>;
		clocks = <&clock_gcc clk_gcc_usb_hs_ahb_clk>,
			 <&clock_gcc clk_gcc_usb_hs_system_clk>,
			 <&clock_gcc clk_gcc_usb2a_phy_sleep_clk>,
			 <&clock_gcc clk_bimc_usb_a_clk>,
			 <&clock_gcc clk_pcnoc_usb_a_clk>,
			 <&clock_gcc clk_gcc_qusb2_phy_clk>,
			 <&clock_gcc clk_gcc_usb2_hs_phy_only_clk>,
			 <&clock_gcc clk_gcc_usb_hs_phy_cfg_ahb_clk>,
			 <&clock_gcc clk_xo_otg_clk>;
		clock-names = "iface_clk", "core_clk", "sleep_clk",
				"bimc_clk", "pcnoc_clk", "phy_reset_clk",
				"phy_por_clk", "phy_csr_clk", "xo";
		qcom,bus-clk-rate = <240000000 0 100000000
				     120000000 0  50000000>;
		qcom,max-nominal-sysclk-rate = <133330000>;
		qcom,max-svs-sysclk-rate = <69500000>;
		qcom,default-mode-svs;

		qcom,usbbam@78c4000 {
			compatible = "qcom,usb-bam-msm";
			reg = <0x78c4000 0x15000>;
			interrupt-parent = <&intc>;
			interrupts = <0 135 0>;
			qcom,bam-type = <1>;
			qcom,usb-bam-num-pipes = <2>;
			qcom,usb-bam-fifo-baseaddr = <0x08603800>;
			qcom,ignore-core-reset-ack;
			qcom,disable-clk-gating;
			qcom,reset-bam-on-disconnect;

			qcom,pipe0 {
				label = "hsusb-qdss-in-0";
				qcom,usb-bam-mem-type = <2>;
				qcom,dir = <1>;
				qcom,pipe-num = <0>;
				qcom,peer-bam = <0>;
				qcom,peer-bam-physical-address = <0x6084000>;
				qcom,src-bam-pipe-index = <0>;
				qcom,dst-bam-pipe-index = <0>;
				qcom,data-fifo-offset = <0x0>;
				qcom,data-fifo-size = <0x600>;
				qcom,descriptor-fifo-offset = <0x600>;
				qcom,descriptor-fifo-size = <0x200>;
			};
		};
	};

	android_usb: android_usb@86000c8 {
		compatible = "qcom,android-usb";
		reg = <0x086000c8 0xc8>;
		qcom,pm-qos-latency = <2 1001 12701>;
	};

	hsic: hsic@7c00000 {
		compatible = "qcom,hsic-peripheral";
		reg = <0x7c00000 0x352>,
		      <0x1100000 0x1200c>;
		interrupts = <0 141 0>, <0 142 0>;
		qcom,hsic-usb-core-id = <1>;
		vdd-supply = <&mdm9607_l9>;
		qcom,vdd-voltage-level = <0 1225000 1225000>;
		qcom,hsic-tlmm-init-seq =
			<0x12008 0x5 0x12004 0x5 0x12000 0x1>;
		qcom,hsic-disable-on-boot;

		clocks = <&clock_gcc clk_gcc_usb_hsic_ahb_clk>,
			 <&clock_gcc clk_gcc_usb_hsic_system_clk>,
			 <&clock_gcc clk_gcc_usb_hsic_clk>,
			 <&clock_gcc clk_gcc_usb_hsic_io_cal_clk>,
			 <&clock_gcc clk_gcc_usb_hsic_io_cal_sleep_clk>;
		clock-names = "iface_clk", "core_clk", "phy_clk",
				"cal_clk", "cal_sleep_clk";

		qcom,msm-bus,name = "hsic";
		qcom,msm-bus,num-cases = <2>;
		qcom,msm-bus,num-paths = <1>;
		qcom,msm-bus,vectors-KBps =
				<85 512 0 0>,
				<85 512 6000  6000>;
		status = "disabled";
	};

	android_usb_hsic: android_usb-hsic {
		compatible = "qcom,android-usb";
		qcom,usb-core-id = <1>;
		status = "disabled";
	};

	hsic_host: hsic_host@7c00000 {
		compatible = "qcom,hsic-host";
		reg = <0x7c00000 0x352>,
		      <0x1100000 0x1200c>;
		interrupts = <0 141 0>, <0 142 0>;
		interrupt-names = "core_irq", "async_irq";
		hsic_vdd_dig-supply = <&mdm9607_l9>;
		hsic,vdd-voltage-level = <0 1225000 1225000>;
		qcom,hsic-tlmm-init-seq =
			<0x12008 0x5 0x12004 0x5 0x12000 0x1>;
		qcom,phy-susp-sof-workaround;
		qcom,disable-internal-clk-gating;

		clocks = <&clock_gcc clk_gcc_usb_hsic_ahb_clk>,
			 <&clock_gcc clk_gcc_usb_hsic_system_clk>,
			 <&clock_gcc clk_gcc_usb_hsic_clk>,
			 <&clock_gcc clk_gcc_usb_hsic_io_cal_clk>,
			 <&clock_gcc clk_gcc_usb_hsic_io_cal_sleep_clk>;
		clock-names = "iface_clk", "core_clk", "phy_clk",
				"cal_clk", "inactivity_clk";

		qcom,msm-bus,name = "hsic";
		qcom,msm-bus,num-cases = <2>;
		qcom,msm-bus,num-paths = <1>;
		qcom,msm-bus,vectors-KBps =
				<85 512 0 0>,
				<85 512 60000 800000>;
		status = "disabled";
	};

	qnand_1: nand@7980000 {
		compatible = "qcom,msm-nand";
		reg = <0x07980000 0x1000>,
		      <0x07984000 0x1a000>;
		reg-names = "nand_phys",
			    "bam_phys";
		qcom,reg-adjustment-offset = <0x4000>;

		interrupts = <0 132 0>;
		interrupt-names = "bam_irq";

		qcom,msm-bus,name = "qpic_nand";
		qcom,msm-bus,num-cases = <2>;
		qcom,msm-bus,num-paths = <1>;

		qcom,msm-bus,vectors-KBps =
			<91 512 0 0>,
			/* Voting for max b/w on PNOC bus for now */
			<91 512 400000 400000>;

		clock-names = "core_clk";
		clocks = <&clock_gcc clk_qpic_clk>;
		status = "disabled";
	};

	sdhc_1: sdhci@7824900 {
		compatible = "qcom,sdhci-msm";
		reg = <0x7824900 0x200>, <0x7824000 0x800>, <0x01111000 0x4>;
		reg-names = "hc_mem", "core_mem", "tlmm_mem";

		qcom,cpu-dma-latency-us = <701>;
		qcom,bus-width = <4>;
		gpios = <&tlmm_pinmux 16 0>, /* CLK */
		      <&tlmm_pinmux 17 0>, /* CMD */
		      <&tlmm_pinmux 15 0>, /* DATA0 */
		      <&tlmm_pinmux 14 0>, /* DATA1 */
		      <&tlmm_pinmux 13 0>, /* DATA2 */
		      <&tlmm_pinmux 12 0>; /* DATA3 */
		qcom,gpio-names = "CLK", "CMD", "DAT0", "DAT1", "DAT2", "DAT3";

		qcom,clk-rates = <400000 20000000 25000000 50000000>;

		clock-names = "iface_clk", "core_clk";
		clocks = <&clock_gcc clk_gcc_sdcc1_ahb_clk>,
		       <&clock_gcc clk_gcc_sdcc1_apps_clk>;

		qcom,msm-bus,name = "sdhc1";
		qcom,msm-bus,num-cases = <8>;
		qcom,msm-bus,num-paths = <1>;
		qcom,msm-bus,vectors-KBps = <78 512 0 0>, /* No vote */
			<78 512 1600 3200>,    /* 400 KB/s*/
			<78 512 80000 160000>, /* 20 MB/s */
			<78 512 100000 200000>, /* 25 MB/s */
			<78 512 200000 400000>, /* 50 MB/s */
			<78 512 400000 800000>, /* 100 MB/s */
			<78 512 800000 800000>, /* 200 MB/s */
			<78 512 2048000 4096000>; /* Max. bandwidth */
			qcom,bus-bw-vectors-bps = <0 400000 20000000 25000000
			50000000 100000000 200000000 4294967295>;

			#address-cells = <0>;
			interrupt-parent = <&sdhc_1>;
			interrupts = <0 1 2>;
			#interrupt-cells = <1>;
			interrupt-map-mask = <0xffffffff>;
			interrupt-map = <0 &intc 0 123 0
				1 &intc 0 138 0
				2 &tlmm_pinmux 59 0x4>;
			interrupt-names = "hc_irq", "pwr_irq", "sdiowakeup_irq";

			qcom,bus-speed-mode = "SDR12", "SDR25", "SDR50",
					"DDR50","SDR104";

			qcom,pm-qos-irq-type = "affine_irq";
			qcom,pm-qos-irq-latency = <2 250>;

			status = "disabled";
	};

	 tsens: tsens@4a8000 {
		compatible = "qcom,mdm9607-tsens";
		reg = <0x4a8000 0x2000>,
			<0xa4000  0x1000>;
		reg-names = "tsens_physical", "tsens_eeprom_physical";
		interrupts = <0 184 0>;
		interrupt-names = "tsens-upper-lower";
		qcom,sensors = <5>;
		qcom,slope = <3000 3000 3000 3000 3000>;
		qcom,sensor-id = <0 1 2 3 4>;
		qcom,temp1-offset = <1 (-4) 4 (-3) (-4)>;
		qcom,temp2-offset = <1 (-2) 8 (-5) (-4)>;
	};

	wcd9xxx_intc: wcd9xxx-irq {
		compatible = "qcom,wcd9xxx-irq";
		interrupt-controller;
		#interrupt-cells = <1>;
		interrupt-parent = <&tlmm_pinmux>;
		qcom,gpio-connect = <&tlmm_pinmux 75 0>;
		interrupt-names = "cdc-int";
	};

	/* achang-20180622, add for audio bring up */
	sound {
		compatible = "qcom,mdm9607-audio-tomtom";
		qcom,model = "mdm9607-tomtom-i2s-snd-card";

		qcom,codec-mclk-clk-freq = <12288000>;
		qcom,prim_mi2s_aux_master = <&prim_master>;
		qcom,prim_mi2s_aux_slave = <&prim_slave>;
		qcom,sec_mi2s_aux_master = <&sec_master>;
		qcom,sec_mi2s_aux_slave = <&sec_slave>;
		asoc-platform = <&pcm0>, <&pcm1>, <&voip>, <&voice>,
				<&loopback>, <&hostless>, <&afe>, <&routing>,
				<&pcm_dtmf>, <&host_pcm>, <&compress>;
		asoc-platform-names = "msm-pcm-dsp.0", "msm-pcm-dsp.1",
				"msm-voip-dsp", "msm-pcm-voice",
				"msm-pcm-loopback", "msm-pcm-hostless",
				"msm-pcm-afe", "msm-pcm-routing",
				"msm-pcm-dtmf", "msm-voice-host-pcm",
				"msm-compress-dsp";
		asoc-cpu = <&dai_pri_auxpcm>, <&dai_sec_auxpcm>,
				<&mi2s_prim>, <&mi2s_sec>, <&dtmf_tx>,
				<&rx_capture_tx>, <&rx_playback_rx>,
				<&tx_capture_tx>, <&tx_playback_rx>,
				<&afe_pcm_rx>, <&afe_pcm_tx>, <&afe_proxy_rx>,
				<&afe_proxy_tx>, <&incall_record_rx>,
				<&incall_record_tx>, <&incall_music_rx>,
				<&dai_pri_tdm_rx_0>, <&dai_pri_tdm_tx_0>,
				<&dai_sec_tdm_rx_0>, <&dai_sec_tdm_tx_0>;
		asoc-cpu-names = "msm-dai-q6-auxpcm.1", "msm-dai-q6-auxpcm.2",
				"msm-dai-q6-mi2s.0", "msm-dai-q6-mi2s.1",
				"msm-dai-stub-dev.4", "msm-dai-stub-dev.5",
				"msm-dai-stub-dev.6", "msm-dai-stub-dev.7",
				"msm-dai-stub-dev.8", "msm-dai-q6-dev.224",
				"msm-dai-q6-dev.225", "msm-dai-q6-dev.241",
				"msm-dai-q6-dev.240", "msm-dai-q6-dev.32771",
				"msm-dai-q6-dev.32772", "msm-dai-q6-dev.32773",
				"msm-dai-q6-tdm.36864", "msm-dai-q6-tdm.36865",
				"msm-dai-q6-tdm.36880", "msm-dai-q6-tdm.36881";
		asoc-codec = <&stub_codec>;
		asoc-codec-names = "msm-stub-codec.1";
	};


	sound-9330 {
		compatible = "qcom,mdm9607-audio-tomtom";
		qcom,model = "mdm9607-tomtom-i2s-snd-card";
		status = "disabled"; /* achang-20180622, we use sound-quectel */

		qcom,audio-routing =
			"RX_BIAS", "MCLK",
			"LDO_H", "MCLK",
			"AMIC2", "MIC BIAS2 External",
			"MIC BIAS2 External", "Headset Mic",
			"AMIC3", "MIC BIAS2 External",
			"MIC BIAS2 External", "ANCRight Headset Mic",
			"AMIC4", "MIC BIAS2 External",
			"MIC BIAS2 External", "ANCLeft Headset Mic",
			"AMIC5", "MIC BIAS1 External",
			"MIC BIAS1 External", "Handset Mic",
			"AMIC6", "MIC BIAS1 External",
			"MIC BIAS1 External", "Handset Mic",
			"DMIC1", "MIC BIAS1 External",
			"MIC BIAS1 External", "Digital Mic1",
			"DMIC3", "MIC BIAS3 External",
			"MIC BIAS3 External", "Digital Mic3";

		qcom,codec-mclk-clk-freq = <12288000>;
		qcom,prim_mi2s_aux_master = <&prim_master>;
		qcom,prim_mi2s_aux_slave = <&prim_slave>;
		qcom,sec_mi2s_aux_master = <&sec_master>;
		qcom,sec_mi2s_aux_slave = <&sec_slave>;
		asoc-platform = <&pcm0>, <&pcm1>, <&voip>, <&voice>,
				<&loopback>, <&hostless>, <&afe>, <&routing>,
				<&pcm_dtmf>, <&host_pcm>, <&compress>;
		asoc-platform-names = "msm-pcm-dsp.0", "msm-pcm-dsp.1",
				"msm-voip-dsp", "msm-pcm-voice",
				"msm-pcm-loopback", "msm-pcm-hostless",
				"msm-pcm-afe", "msm-pcm-routing",
				"msm-pcm-dtmf", "msm-voice-host-pcm",
				"msm-compress-dsp";
		asoc-cpu = <&dai_pri_auxpcm>, <&dai_sec_auxpcm>,
				<&mi2s_prim>, <&mi2s_sec>, <&dtmf_tx>,
				<&rx_capture_tx>, <&rx_playback_rx>,
				<&tx_capture_tx>, <&tx_playback_rx>,
				<&afe_pcm_rx>, <&afe_pcm_tx>, <&afe_proxy_rx>,
				<&afe_proxy_tx>, <&incall_record_rx>,
				<&incall_record_tx>, <&incall_music_rx>,
				<&dai_pri_tdm_rx_0>, <&dai_pri_tdm_tx_0>,
				<&dai_sec_tdm_rx_0>, <&dai_sec_tdm_tx_0>;
		asoc-cpu-names = "msm-dai-q6-auxpcm.1", "msm-dai-q6-auxpcm.2",
				"msm-dai-q6-mi2s.0", "msm-dai-q6-mi2s.1",
				"msm-dai-stub-dev.4", "msm-dai-stub-dev.5",
				"msm-dai-stub-dev.6", "msm-dai-stub-dev.7",
				"msm-dai-stub-dev.8", "msm-dai-q6-dev.224",
				"msm-dai-q6-dev.225", "msm-dai-q6-dev.241",
				"msm-dai-q6-dev.240", "msm-dai-q6-dev.32771",
				"msm-dai-q6-dev.32772", "msm-dai-q6-dev.32773",
				"msm-dai-q6-tdm.36864", "msm-dai-q6-tdm.36865",
				"msm-dai-q6-tdm.36880", "msm-dai-q6-tdm.36881";
		asoc-codec = <&stub_codec>;
		asoc-codec-names = "msm-stub-codec.1";
	};

	sound-9306 {
		compatible = "qcom,mdm9607-audio-tapan";
		qcom,model = "mdm9607-tapan-i2s-snd-card";
		status = "disabled";

		qcom,audio-routing =
			"RX_BIAS", "MCLK",
			"LDO_H", "MCLK",
			"SPK_OUT", "MCLK",
			"AMIC1", "MIC BIAS1 External",
			"MIC BIAS1 External", "Handset Mic",
			"AMIC2", "MIC BIAS2 External",
			"MIC BIAS2 External", "Headset Mic",
			"AMIC4", "MIC BIAS2 External",
			"MIC BIAS2 External", "ANCRight Headset Mic",
			"AMIC5", "MIC BIAS2 External",
			"MIC BIAS2 External", "ANCLeft Headset Mic",
			"DMIC1", "MIC BIAS1 External",
			"MIC BIAS1 External", "Digital Mic1",
			"DMIC2", "MIC BIAS1 External",
			"MIC BIAS1 External", "Digital Mic2",
			"DMIC3", "MIC BIAS3 External",
			"MIC BIAS3 External", "Digital Mic3",
			"DMIC4", "MIC BIAS3 External",
			"MIC BIAS3 External", "Digital Mic4";

		qcom,codec-mclk-clk-freq = <12288000>;
		qcom,prim_mi2s_aux_master = <&prim_master>;
		qcom,prim_mi2s_aux_slave = <&prim_slave>;
		qcom,sec_mi2s_aux_master = <&sec_master>;
		qcom,sec_mi2s_aux_slave = <&sec_slave>;
		asoc-platform = <&pcm0>, <&pcm1>, <&voip>, <&voice>,
				<&loopback>, <&hostless>, <&afe>, <&routing>,
				<&pcm_dtmf>, <&host_pcm>, <&compress>;
		asoc-platform-names = "msm-pcm-dsp.0", "msm-pcm-dsp.1",
				"msm-voip-dsp", "msm-pcm-voice",
				"msm-pcm-loopback", "msm-pcm-hostless",
				"msm-pcm-afe", "msm-pcm-routing",
				"msm-pcm-dtmf", "msm-voice-host-pcm",
				"msm-compress-dsp";
		asoc-cpu = <&dai_pri_auxpcm>, <&dai_sec_auxpcm>,
				<&mi2s_prim>, <&mi2s_sec>, <&dtmf_tx>,
				<&rx_capture_tx>, <&rx_playback_rx>,
				<&tx_capture_tx>, <&tx_playback_rx>,
				<&afe_pcm_rx>, <&afe_pcm_tx>, <&afe_proxy_rx>,
				<&afe_proxy_tx>, <&incall_record_rx>,
				<&incall_record_tx>, <&incall_music_rx>;
		asoc-cpu-names = "msm-dai-q6-auxpcm.1", "msm-dai-q6-auxpcm.2",
				"msm-dai-q6-mi2s.0", "msm-dai-q6-mi2s.1",
				"msm-dai-stub-dev.4", "msm-dai-stub-dev.5",
				"msm-dai-stub-dev.6", "msm-dai-stub-dev.7",
				"msm-dai-stub-dev.8", "msm-dai-q6-dev.224",
				"msm-dai-q6-dev.225", "msm-dai-q6-dev.241",
				"msm-dai-q6-dev.240", "msm-dai-q6-dev.32771",
				"msm-dai-q6-dev.32772", "msm-dai-q6-dev.32773";
		asoc-codec = <&stub_codec>;
		asoc-codec-names = "msm-stub-codec.1";
	};

	qcom,msm-adsp-loader {
		compatible = "qcom,adsp-loader";
		qcom,adsp-state = <0>;
		qcom,proc-img-to-load = "modem";
	};

	qcom,msm-audio-ion {
		compatible = "qcom,msm-audio-ion";
		qcom,scm-mp-enabled;
		memory-region = <&audio_mem>;
	};

	pcm0: qcom,msm-pcm {
		compatible = "qcom,msm-pcm-dsp";
		qcom,msm-pcm-dsp-id = <0>;
	};

	routing: qcom,msm-pcm-routing {
		compatible = "qcom,msm-pcm-routing";
	};

	pcm1: qcom,msm-pcm-low-latency {
		compatible = "qcom,msm-pcm-dsp";
		qcom,msm-pcm-dsp-id = <1>;
		qcom,msm-pcm-low-latency;
		qcom,latency-level = "ultra";
	};

	qcom,msm-compr-dsp {
		compatible = "qcom,msm-compr-dsp";
	};

	voip: qcom,msm-voip-dsp {
		compatible = "qcom,msm-voip-dsp";
	};

	voice: qcom,msm-pcm-voice {
		compatible = "qcom,msm-pcm-voice";
		qcom,destroy-cvd;
	};

	stub_codec: qcom,msm-stub-codec {
		compatible = "qcom,msm-stub-codec";
	};

	qcom,msm-dai-fe {
		compatible = "qcom,msm-dai-fe";
	};

	afe: qcom,msm-pcm-afe {
		compatible = "qcom,msm-pcm-afe";
	};

	hostless: qcom,msm-pcm-hostless {
		compatible = "qcom,msm-pcm-hostless";
	};

	host_pcm: qcom,msm-voice-host-pcm {
		compatible = "qcom,msm-voice-host-pcm";
	};

	loopback: qcom,msm-pcm-loopback {
		compatible = "qcom,msm-pcm-loopback";
	};

	compress: qcom,msm-compress-dsp {
		compatible = "qcom,msm-compress-dsp";
		qcom,adsp-version = "MDSP 2.8";
	};

	 qcom,msm-dai-stub {
		compatible = "qcom,msm-dai-stub";
		dtmf_tx: qcom,msm-dai-stub-dtmf-tx {
			compatible = "qcom,msm-dai-stub-dev";
			qcom,msm-dai-stub-dev-id = <4>;
		};

		rx_capture_tx: qcom,msm-dai-stub-host-rx-capture-tx {
			compatible = "qcom,msm-dai-stub-dev";
			qcom,msm-dai-stub-dev-id = <5>;
		};

		rx_playback_rx: qcom,msm-dai-stub-host-rx-playback-rx {
			compatible = "qcom,msm-dai-stub-dev";
			qcom,msm-dai-stub-dev-id = <6>;
	       };

		tx_capture_tx: qcom,msm-dai-stub-host-tx-capture-tx {
			compatible = "qcom,msm-dai-stub-dev";
			qcom,msm-dai-stub-dev-id = <7>;
		};

		tx_playback_rx: qcom,msm-dai-stub-host-tx-playback-rx {
			compatible = "qcom,msm-dai-stub-dev";
			qcom,msm-dai-stub-dev-id = <8>;
		};
	};

	qcom,msm-dai-q6 {
		compatible = "qcom,msm-dai-q6";
		afe_pcm_rx: qcom,msm-dai-q6-be-afe-pcm-rx {
			compatible = "qcom,msm-dai-q6-dev";
			qcom,msm-dai-q6-dev-id = <224>;
		};

		afe_pcm_tx: qcom,msm-dai-q6-be-afe-pcm-tx {
			compatible = "qcom,msm-dai-q6-dev";
			qcom,msm-dai-q6-dev-id = <225>;
		};

		afe_proxy_rx: qcom,msm-dai-q6-afe-proxy-rx {
			compatible = "qcom,msm-dai-q6-dev";
			qcom,msm-dai-q6-dev-id = <241>;
		};

		afe_proxy_tx: qcom,msm-dai-q6-afe-proxy-tx {
			compatible = "qcom,msm-dai-q6-dev";
			qcom,msm-dai-q6-dev-id = <240>;
		};

		incall_record_rx: qcom,msm-dai-q6-incall-record-rx {
			compatible = "qcom,msm-dai-q6-dev";
			qcom,msm-dai-q6-dev-id = <32771>;
		};

		incall_record_tx: qcom,msm-dai-q6-incall-record-tx {
			compatible = "qcom,msm-dai-q6-dev";
			qcom,msm-dai-q6-dev-id = <32772>;
		};

		incall_music_rx: qcom,msm-dai-q6-incall-music-rx {
			compatible = "qcom,msm-dai-q6-dev";
			qcom,msm-dai-q6-dev-id = <32773>;
		};
	};

	pcm_dtmf: qcom,msm-pcm-dtmf {
		compatible = "qcom,msm-pcm-dtmf";
	};

	dai_pri_auxpcm: qcom,msm-pri-auxpcm {
		compatible = "qcom,msm-auxpcm-dev";
		qcom,msm-cpudai-auxpcm-mode = <0>, <0>;
		qcom,msm-cpudai-auxpcm-sync = <1>, <1>;
		qcom,msm-cpudai-auxpcm-frame = <5>, <4>;
		qcom,msm-cpudai-auxpcm-quant = <2>, <2>;
		qcom,msm-cpudai-auxpcm-num-slots = <1>, <1>;
		qcom,msm-cpudai-auxpcm-slot-mapping = <1>, <1>;
		qcom,msm-cpudai-auxpcm-data = <0>, <0>;
		qcom,msm-cpudai-auxpcm-pcm-clk-rate = <2048000>, <2048000>;
		qcom,msm-auxpcm-interface = "primary";
		qcom,msm-cpudai-afe-clk-ver = <2>;
	};

	dai_sec_auxpcm: qcom,msm-sec-auxpcm {
		compatible = "qcom,msm-auxpcm-dev";
		qcom,msm-cpudai-auxpcm-mode = <0>, <0>;
		qcom,msm-cpudai-auxpcm-sync = <1>, <1>;
		qcom,msm-cpudai-auxpcm-frame = <5>, <4>;
		qcom,msm-cpudai-auxpcm-quant = <2>, <2>;
		qcom,msm-cpudai-auxpcm-num-slots = <1>, <1>;
		qcom,msm-cpudai-auxpcm-slot-mapping = <1>, <1>;
		qcom,msm-cpudai-auxpcm-data = <0>, <0>;
		qcom,msm-cpudai-auxpcm-pcm-clk-rate = <2048000>, <2048000>;
		qcom,msm-auxpcm-interface = "secondary";
		qcom,msm-cpudai-afe-clk-ver = <2>;
	};

	qcom,msm-dai-mi2s {
		compatible = "qcom,msm-dai-mi2s";
		mi2s_prim: qcom,msm-dai-q6-mi2s-prim {
			compatible = "qcom,msm-dai-q6-mi2s";
			qcom,msm-dai-q6-mi2s-dev-id = <0>;
			qcom,msm-mi2s-rx-lines = <2>;
			qcom,msm-mi2s-tx-lines = <1>;
		};
		mi2s_sec: qcom,msm-dai-q6-mi2s-sec {
			compatible = "qcom,msm-dai-q6-mi2s";
			qcom,msm-dai-q6-mi2s-dev-id = <1>;
			qcom,msm-mi2s-rx-lines = <2>;
			qcom,msm-mi2s-tx-lines = <1>;
		};
	};

	prim_master: prim_master_pinctrl {
		compatible = "qcom,wcd-gpio-ctrl";
		pinctrl-names = "aud_active", "aud_sleep";
		pinctrl-0 = <&pri_ws_active_master
				&pri_sck_active_master
				&pri_dout_active
				&pri_din_active>;
		pinctrl-1 = <&pri_ws_sleep
				&pri_sck_sleep
				&pri_dout_sleep
				&pri_din_sleep>;
		qcom,mi2s-auxpcm-cdc-gpios;
	};

	prim_slave: prim_slave_pinctrl {
		compatible = "qcom,wcd-gpio-ctrl";
		pinctrl-names = "aud_active", "aud_sleep";
		pinctrl-0 = <&pri_ws_active_slave
				&pri_sck_active_slave
				&pri_dout_active
				&pri_din_active>;
		pinctrl-1 = <&pri_ws_sleep
				&pri_sck_sleep
				&pri_dout_sleep
				&pri_din_sleep>;
		qcom,mi2s-auxpcm-cdc-gpios;
	};

	sec_master: sec_master_pinctrl {
		compatible = "qcom,wcd-gpio-ctrl";
		pinctrl-names = "aud_active", "aud_sleep";
		pinctrl-0 = <&sec_ws_active_master
				&sec_sck_active_master
				&sec_dout_active
				&sec_din_active>;
		pinctrl-1 = <&sec_ws_sleep
				&sec_sck_sleep
				&sec_dout_sleep
				&sec_din_sleep>;
		qcom,mi2s-auxpcm-cdc-gpios;
	};

	sec_slave: sec_slave_pinctrl {
		compatible = "qcom,wcd-gpio-ctrl";
		pinctrl-names = "aud_active", "aud_sleep";
		pinctrl-0 = <&sec_ws_active_slave
				&sec_sck_active_slave
				&sec_dout_active
				&sec_din_active>;
		pinctrl-1 = <&sec_ws_sleep
				&sec_sck_sleep
				&sec_dout_sleep
				&sec_din_sleep>;
		qcom,mi2s-auxpcm-cdc-gpios;
	};

	qcom,msm-thermal {
		compatible = "qcom,msm-thermal";
		qcom,sensor-id = <4>;
		qcom,poll-ms = <250>;
		qcom,limit-temp = <60>;
		qcom,temp-hysteresis = <10>;
		qcom,freq-step = <2>;
		qcom,freq-mitigation-temp = <105>;
		qcom,freq-mitigation-temp-hysteresis = <15>;
		qcom,freq-mitigation-value = <800000>;
		qcom,disable-cx-phase-ctrl;
		qcom,disable-gfx-phase-ctrl;
		qcom,disable-psm;
		qcom,disable-ocr;
		qcom,mx-restriction-temp = <10>;
		qcom,mx-restriction-temp-hysteresis = <5>;
		qcom,mx-restriction-sensor_id = <0>; //bowen.gu 20210220 only monitor sensor 0 for mx-restriction
		qcom,mx-retention-min =
			<RPM_SMD_REGULATOR_LEVEL_NOM_PLUS>;
		vdd-mx-supply = <&mdm9607_l12_floor_level>;
		qcom,vdd-restriction-temp = <10>;
		qcom,vdd-restriction-temp-hysteresis = <15>;
		qcom,vdd-restriction-sensor-id = <0>; ///bowen.gu 20210220 only monitor sensor 0 for vdd-restriction
		vdd-dig-supply = <&mdm9607_s3_floor_level>;
		qcom,therm-ddr-lm-info = <2 78 70>;

		qcom,vdd-dig-rstr{
			qcom,vdd-rstr-reg = "vdd-dig";
			qcom,levels = <RPM_SMD_REGULATOR_LEVEL_TURBO_NO_CPR
					RPM_SMD_REGULATOR_LEVEL_BINNING
					RPM_SMD_REGULATOR_LEVEL_BINNING>;
			qcom,min-level = <RPM_SMD_REGULATOR_LEVEL_RETENTION>;
		};

		 msm_thermal_freq: qcom,vdd-apps-rstr {
			qcom,vdd-rstr-reg = "vdd-apps";
			qcom,levels = <998400>;
			qcom,freq-req;
		};
	};

	qcom,sensor-information {
		compatible = "qcom,sensor-information";
		sensor_information0: qcom,sensor-information-0 {
			qcom,sensor-type = "tsens";
			qcom,sensor-name = "tsens_tz_sensor0";
		};

		sensor_information1: qcom,sensor-information-1 {
			qcom,sensor-type =  "tsens";
			qcom,sensor-name = "tsens_tz_sensor1";
		};

		sensor_information2: qcom,sensor-information-2 {
			qcom,sensor-type =  "tsens";
			qcom,sensor-name = "tsens_tz_sensor2";
		};

		sensor_information3: qcom,sensor-information-3 {
			qcom,sensor-type = "tsens";
			qcom,sensor-name = "tsens_tz_sensor3";
		};

		sensor_information4: qcom,sensor-information-4 {
			qcom,sensor-type = "tsens";
			qcom,sensor-name = "tsens_tz_sensor4";
		};

		sensor_information5: qcom,sensor-information-5 {
			qcom,sensor-type = "adc";
			qcom,sensor-name = "pa_therm0";
		};

		sensor_information6: qcom,sensor-information-6 {
			qcom,sensor-type = "adc";
			qcom,sensor-name = "pa_therm1";
		};

		sensor_information7: qcom,sensor-information-7 {
			qcom,sensor-type = "adc";
			qcom,sensor-name = "xo_therm";
		};

		sensor_information8: qcom,sensor-information-8 {
			qcom,sensor-type = "adc";
			qcom,sensor-name = "xo_therm_amux";
		};
	};

	mitigation_profile0: qcom,limit_info-0 {
		qcom,temperature-sensor = <&sensor_information4>;
		qcom,boot-frequency-mitigate;
		qcom,emergency-frequency-mitigate;
	};

	qcom,ipc-spinlock@1905000 {
		compatible = "qcom,ipc-spinlock-sfpb";
		reg = <0x1905000 0x8000>;
		qcom,num-locks = <8>;
	};

	qcom,smem@87d00000 {
		compatible = "qcom,smem";
		reg = <0x87d00000 0x100000>,
			<0x0b011008 0x4>,
			<0x60000 0x8000>,
			<0x193d000 0x8>;
		reg-names = "smem", "irq-reg-base", "aux-mem1",
				"smem_targ_info_reg";
		qcom,mpu-enabled;

		qcom,smd-modem {
			compatible = "qcom,smd";
			qcom,smd-edge = <0>;
			qcom,smd-irq-offset = <0x0>;
			qcom,smd-irq-bitmask = <0x1000>;
			interrupts = <0 25 1>;
			label = "modem";
			qcom,not-loadable;
		};

		qcom,smsm-modem {
			compatible = "qcom,smsm";
			qcom,smsm-edge = <0>;
			qcom,smsm-irq-offset = <0x0>;
			qcom,smsm-irq-bitmask = <0x2000>;
			interrupts = <0 26 1>;
		};

		qcom,smd-rpm {
			compatible = "qcom,smd";
			qcom,smd-edge = <15>;
			qcom,smd-irq-offset = <0x0>;
			qcom,smd-irq-bitmask = <0x1>;
			interrupts = <0 168 1>;
			label = "rpm";
			qcom,irq-no-suspend;
			qcom,not-loadable;
		};
	};

	rpm_bus: qcom,rpm-smd {
		compatible = "qcom,rpm-smd";
		rpm-channel-name = "rpm_requests";
		rpm-channel-type = <15>; /* SMD_APPS_RPM */
	};

	qcom,smdtty {
		compatible = "qcom,smdtty";

		smdtty_data1: qcom,smdtty-data1 {
			qcom,smdtty-remote = "modem";
			qcom,smdtty-port-name = "DATA1";
			quectel,smdtty-writeable = "0";
		};

		smdtty_data2: qcom,smdtty-data2 {
			qcom,smdtty-remote = "modem";
			qcom,smdtty-port-name = "DATA2";
		};

		smdtty_data3: qcom,smdtty-data3 {
			qcom,smdtty-remote = "modem";
			qcom,smdtty-port-name = "DATA3";
		};

		smdtty_data4: qcom,smdtty-data4 {
			qcom,smdtty-remote = "modem";
			qcom,smdtty-port-name = "DATA4";
		};
		/*modified by max.tang@20160118. del Data11 from APP to be used by second USB AT port*/
		/*smdtty_data11: qcom,smdtty-data11 {
			qcom,smdtty-remote = "modem";
			qcom,smdtty-port-name = "DATA11";
		};*/

		smdtty_data21: qcom,smdtty-data21 {
			qcom,smdtty-remote = "modem";
			qcom,smdtty-port-name = "DATA21";
		};

		smdtty_loopback: smdtty-loopback {
			qcom,smdtty-remote = "modem";
			qcom,smdtty-port-name = "LOOPBACK";
			qcom,smdtty-dev-name = "LOOPBACK_TTY";
		};
	};

	qcom,smdpkt {
		compatible = "qcom,smdpkt";

		qcom,smdpkt-data5-cntl {
			qcom,smdpkt-remote = "modem";
			qcom,smdpkt-port-name = "DATA5_CNTL";
			qcom,smdpkt-dev-name = "smdcntl0";
		};

		qcom,smdpkt-data22 {
			qcom,smdpkt-remote = "modem";
			qcom,smdpkt-port-name = "DATA22";
			qcom,smdpkt-dev-name = "smd22";
		};

		qcom,smdpkt-data40-cntl {
			qcom,smdpkt-remote = "modem";
			qcom,smdpkt-port-name = "DATA40_CNTL";
			qcom,smdpkt-dev-name = "smdcntl8";
		};

		qcom,smdpkt-apr-apps2 {
			qcom,smdpkt-remote = "modem";
			qcom,smdpkt-port-name = "apr_apps2";
			qcom,smdpkt-dev-name = "apr_apps2";
		};

		qcom,smdpkt-loopback {
			qcom,smdpkt-remote = "modem";
			qcom,smdpkt-port-name = "LOOPBACK";
			qcom,smdpkt-dev-name = "smd_pkt_loopback";
		};
	};

	qcom,ipc_router {
		compatible = "qcom,ipc_router";
		qcom,node-id = <1>;
	};

	qcom,ipc_router_modem_xprt {
		compatible = "qcom,ipc_router_smd_xprt";
		qcom,ch-name = "IPCRTR";
		qcom,xprt-remote = "modem";
		qcom,xprt-linkid = <1>;
		qcom,xprt-version = <1>;
		qcom,fragmented-data;
		qcom,disable-pil-loading;
	};

	qcom,bam_dmux@4044000 {
		compatible = "qcom,bam_dmux";
		reg = <0x4044000 0x19000>;
		interrupts = <0 29 1>;
		qcom,rx-ring-size = <32>;
		qcom,max-rx-mtu = <4096>;
		qcom,fast-shutdown;
	};

	spmi_bus: qcom,spmi@200f000 {
		compatible = "qcom,spmi-pmic-arb";
		reg = <0x200f000 0x1000>,
			<0x2400000 0x800000>,
			<0x2c00000 0x800000>,
			<0x3800000 0x200000>,
			<0x200a000 0x2100>;
		reg-names = "core", "chnls", "obsrvr", "intr", "cnfg";
		interrupts = <0 190 0>;
		qcom,pmic-arb-channel = <0>;
		qcom,pmic-arb-max-peripherals = <128>;
		qcom,pmic-arb-max-periph-interrupts = <128>;
		qcom,pmic-arb-ee = <0>;
		#interrupt-cells = <3>;
		interrupt-controller;
		#address-cells = <1>;
		#size-cells = <0>;
		cell-index = <0>;
	};

	/*Start:Add spi3, spi5 node, gale 2018-3-14
	* according to AG35 Hardware Design, support three spi, spi_6 is actived,
	* and spi_3, spi_5 is inactived by default, user could enable it.
	*/
	/*BLSP1 QUP3--->gpio0,1,2,3, gale 2018-3-14 */
	spi_3: spi@78b7000 {
		compatible = "qcom,spi-qup-v2";
		#address-cells = <1>;
		#size-cells = <0>;
		reg-names = "spi_physical", "spi_bam_physical";
		reg = <0x78b7000 0x600>,
		      <0x7884000 0x2b000>;
		interrupt-names = "spi_irq", "spi_bam_irq";
		interrupts = <0 97 0>, <0 238 0>;
		spi-max-frequency = <19200000>;
		pinctrl-names = "spi_default", "spi_sleep";
		pinctrl-0 = <&spi3_default &spi3_cs0_active>;
		pinctrl-1 = <&spi3_sleep &spi3_cs0_sleep>;
		clocks = <&clock_gcc clk_gcc_blsp1_ahb_clk>,
			 <&clock_gcc clk_gcc_blsp1_qup3_spi_apps_clk>;
		clock-names = "iface_clk", "core_clk";
		qcom,infinite-mode = <0>;
		qcom,use-bam;
		qcom,use-pinctrl;
		qcom,ver-reg-exists;
		qcom,bam-consumer-pipe-index = <16>;
		qcom,bam-producer-pipe-index = <17>;
		qcom,master-id = <86>;
		status = "disabled";
	}; 

	/*BLSP1 QUP5--->gpio8,9,10,11, gale 2018-3-14*/
	spi_5: spi@78b9000 { 
		compatible = "qcom,spi-qup-v2";
		#address-cells = <1>;
		#size-cells = <0>;
		reg-names = "spi_physical", "spi_bam_physical";
		reg = <0x78b9000 0x600>,
		      <0x7884000 0x2b000>;
		interrupt-names = "spi_irq", "spi_bam_irq";
		interrupts = <0 99 0>, <0 238 0>;
		spi-max-frequency = <19200000>;
		pinctrl-names = "spi_default", "spi_sleep";
		pinctrl-0 = <&spi5_default &spi5_cs0_active>;
		pinctrl-1 = <&spi5_sleep &spi5_cs0_sleep>;
		clocks = <&clock_gcc clk_gcc_blsp1_ahb_clk>,
			 <&clock_gcc clk_gcc_blsp1_qup5_spi_apps_clk>;
		clock-names = "iface_clk", "core_clk";
		qcom,infinite-mode = <0>;
		qcom,use-bam;
		qcom,use-pinctrl;
		qcom,ver-reg-exists;
		qcom,bam-consumer-pipe-index = <20>;
		qcom,bam-producer-pipe-index = <21>;
		qcom,master-id = <86>;
		status = "disabled";
	};
	/*End:Add spi3, spi5 node, gale 2018-3-14*/ 
	 
		/*BLSP QUP6*/
	spi_6: spi@78ba000 { 
		compatible = "qcom,spi-qup-v2";
		#address-cells = <1>;
		#size-cells = <0>;
		reg-names = "spi_physical", "spi_bam_physical";
		reg = <0x78ba000 0x600>,
		      <0x7884000 0x2b000>;
		interrupt-names = "spi_irq", "spi_bam_irq";
		interrupts = <0 100 0>, <0 238 0>;
		spi-max-frequency = <19200000>;
		pinctrl-names = "spi_default", "spi_sleep";
		pinctrl-0 = <&spi6_default &spi6_cs0_active>;
		pinctrl-1 = <&spi6_sleep &spi6_cs0_sleep>;
		clocks = <&clock_gcc clk_gcc_blsp1_ahb_clk>,
			 <&clock_gcc clk_gcc_blsp1_qup6_spi_apps_clk>;
		clock-names = "iface_clk", "core_clk";
		qcom,infinite-mode = <0>;
		qcom,use-bam;
		qcom,use-pinctrl;
		qcom,ver-reg-exists;
		qcom,bam-consumer-pipe-index = <22>;
		qcom,bam-producer-pipe-index = <23>;
		qcom,master-id = <86>;
		status = "disabled";
	};
	 /*end cullen.wang*/ 

	qcom,mss@4080000 {
		compatible = "qcom,pil-q6v55-mss";
		reg =   <0x04080000 0x100>,
			<0x0194f000 0x010>,
			<0x01950000 0x008>,
			<0x01951000 0x008>,
			<0x04020000 0x040>,
			<0x0183e000 0x004>;
		reg-names = "qdsp6_base", "halt_q6", "halt_modem", "halt_nc",
				"rmb_base", "restart_reg";

		interrupts = <0 24 1>;
		vdd_cx-supply = <&mdm9607_s3_level>;
		vdd_cx-voltage = <RPM_SMD_REGULATOR_LEVEL_TURBO>;
		vdd_mx-supply = <&mdm9607_l12_level>;
		vdd_mx-uV = <RPM_SMD_REGULATOR_LEVEL_TURBO>;
		vdd_pll-supply = <&mdm9607_l3>;
		qcom,vdd_pll = <1800000>;

		clocks = <&clock_gcc clk_xo_pil_mss_clk>,
			 <&clock_gcc clk_gcc_mss_cfg_ahb_clk>,
			 <&clock_gcc clk_gcc_mss_q6_bimc_axi_clk>,
			 <&clock_gcc clk_gcc_boot_rom_ahb_clk>;
		clock-names = "xo", "iface_clk", "bus_clk", "mem_clk";
		qcom,proxy-clock-names = "xo";
		qcom,active-clock-names = "iface_clk", "bus_clk", "mem_clk";

		qcom,firmware-name = "modem";
		qcom,pil-self-auth;
		qcom,override-acc-1 = <0x80800000>;
		qcom,sysmon-id = <0>;
		qcom,ssctl-instance-id = <0x12>;
		qcom,qdsp6v56-1-8-inrush-current;

		/* GPIO inputs from mss */
		qcom,gpio-err-fatal = <&smp2pgpio_ssr_smp2p_1_in 0 0>;
		qcom,gpio-err-ready = <&smp2pgpio_ssr_smp2p_1_in 1 0>;
		qcom,gpio-proxy-unvote = <&smp2pgpio_ssr_smp2p_1_in 2 0>;
		qcom,gpio-stop-ack = <&smp2pgpio_ssr_smp2p_1_in 3 0>;
		qcom,gpio-shutdown-ack = <&smp2pgpio_ssr_smp2p_1_in 7 0>;

		/* GPIO output to mss */
		qcom,gpio-force-stop = <&smp2pgpio_ssr_smp2p_1_out 0 0>;
		memory-region = <&modem_adsp_mem>;
	};

	sdhc_2: sdhci@7864900 {
		compatible = "qcom,sdhci-msm";
		reg = <0x07864900 0x200>, <0x07864000 0x800>;
		reg-names = "hc_mem", "core_mem";

		interrupts = <0 125 0>, <0 221 0>;
		interrupt-names = "hc_irq", "pwr_irq";

		qcom,bus-width = <4>;

		qcom,devfreq,freq-table = <25000000 50000000>;

		qcom,msm-bus,name = "sdhc2";
		qcom,msm-bus,num-cases = <8>;
		qcom,msm-bus,num-paths = <1>;
		qcom,msm-bus,vectors-KBps = <81 512 0 0>, /* No vote */
				<81 512 1600 3200>,    /* 400 KB/s*/
				<81 512 80000 160000>, /* 20 MB/s */
				<81 512 100000 200000>, /* 25 MB/s */
				<81 512 200000 400000>, /* 50 MB/s */
				<81 512 400000 800000>, /* 100 MB/s */
				<81 512 800000 800000>, /* 200 MB/s */
				<81 512 2048000 4096000>; /* Max. bandwidth */
		qcom,bus-bw-vectors-bps = <0 400000 20000000 25000000 50000000
						100000000 200000000 4294967295>;

		clocks = <&clock_gcc clk_gcc_sdcc2_ahb_clk>,
			 <&clock_gcc clk_gcc_sdcc2_apps_clk>;
		clock-names = "iface_clk", "core_clk";

		qcom,clk-rates = <400000 25000000 50000000>;

		qcom,pm-qos-irq-type = "affine_irq";
		qcom,pm-qos-irq-latency = <2 250>;

		status = "disabled";
	};

	qrng: rng@22000 {
		compatible = "qcom,msm-rng";
		reg = <0x22000 0x140>;
		qcom,msm-rng-iface-clk;
		qcom,msm-bus,name = "msm-rng-noc";
		qcom,msm-bus,num-cases = <2>;
		qcom,msm-bus,num-paths = <1>;
		qcom,msm-bus,vectors-KBps =
			<1 618 0 0>,
			<1 618 0 800>;
		clocks = <&clock_gcc clk_gcc_prng_ahb_clk>;
		clock-names = "iface_clk";
	};

	qcom_crypto: qcrypto@720000 {
		compatible = "qcom,qcrypto";
		reg = <0x720000 0x20000>,
			<0x704000 0x20000>;
		reg-names = "crypto-base","crypto-bam-base";
		interrupts = <0 207 0>;
		qcom,bam-pipe-pair = <2>;
		qcom,ce-hw-instance = <0>;
		qcom,ce-device = <0>;
		qcom,clk-mgmt-sus-res;
		qcom,msm-bus,name = "qcrypto-noc";
		qcom,msm-bus,num-cases = <2>;
		qcom,msm-bus,num-paths = <1>;
		qcom,msm-bus,vectors-KBps =
				<47 512 0 0>,
				<47 512 393600 800000>;
		clocks = <&clock_gcc clk_crypto_clk_src>,
			 <&clock_gcc clk_gcc_crypto_clk>,
			 <&clock_gcc clk_gcc_crypto_ahb_clk>,
			 <&clock_gcc clk_gcc_crypto_axi_clk>;
		clock-names = "core_clk_src", "core_clk",
				"iface_clk", "bus_clk";
		qcom,use-sw-aes-cbc-ecb-ctr-algo;
		qcom,use-sw-aes-xts-algo;
		qcom,use-sw-aes-ccm-algo;
		qcom,use-sw-ahash-algo;
		qcom,use-sw-hmac-algo;
		qcom,use-sw-aead-algo;
		qcom,ce-opp-freq = <100000000>;
	};

	qcom_qcedev: qcedev@720000 {
		compatible = "qcom,qcedev";
		reg = <0x720000 0x20000>,
			<0x704000 0x20000>;
		reg-names = "crypto-base","crypto-bam-base";
		interrupts = <0 207 0>;
		qcom,bam-pipe-pair = <1>;
		qcom,ce-hw-instance = <0>;
		qcom,ce-device = <0>;
		qcom,ce-hw-shared;
		qcom,msm-bus,name = "qcedev-noc";
		qcom,msm-bus,num-cases = <2>;
		qcom,msm-bus,num-paths = <1>;
		qcom,msm-bus,vectors-KBps =
				<47 512 0 0>,
				<47 512 3936000 393600>;
		clocks = <&clock_gcc clk_crypto_clk_src>,
			 <&clock_gcc clk_gcc_crypto_clk>,
			 <&clock_gcc clk_gcc_crypto_ahb_clk>,
			 <&clock_gcc clk_gcc_crypto_axi_clk>;
		clock-names = "core_clk_src", "core_clk",
				"iface_clk", "bus_clk";
		qcom,ce-opp-freq = <100000000>;
	};

	qcom_seecom: qseecom@88000000{
		compatible = "qcom,qseecom";
		reg = <0x88000000 0x500000>;
		reg-names = "secapp-region";
		qcom,hlos-ce-hw-instance = <0>;
		qcom,qsee-ce-hw-instance = <0>;
		qcom,msm-bus,name = "qseecom-noc";
		qcom,msm-bus,num-cases = <4>;
		qcom,msm-bus,num-paths = <1>;
		qcom,support-bus-scaling;
		qcom,msm-bus,vectors-KBps =
				<47 512 0 0>,
				<47 512 0 0>,
				<47 512 120000 1200000>,
				<47 512 393600 3936000>;
		clocks = <&clock_gcc clk_crypto_clk_src>,
			<&clock_gcc clk_gcc_crypto_clk>,
			<&clock_gcc clk_gcc_crypto_ahb_clk>,
			<&clock_gcc clk_gcc_crypto_axi_clk>;
		clock-names = "core_clk_src", "core_clk",
				"iface_clk", "bus_clk";
		qcom,ce-opp-freq = <100000000>;
        qcom,qsee-reentrancy-support = <2>;
		status = "ok";
	};

	qcom_smcinvoke: smcinvoke@88000000 {
		compatible = "qcom,smcinvoke";
		reg = <0x88000000 0x500000>;
		qcom,clock-support;
		qcom,msm-bus,name = "smcinvoke-noc";
		qcom,msm-bus,num-cases = <2>;
		qcom,msm-bus,num-paths = <1>;
		qcom,msm-bus,vectors-KBps =
				<47 512 0 0>,
				<47 512 393600 3936000>;
		clocks = <&clock_gcc clk_crypto_clk_src>,
			<&clock_gcc clk_gcc_crypto_clk>,
			<&clock_gcc clk_gcc_crypto_ahb_clk>,
			<&clock_gcc clk_gcc_crypto_axi_clk>;
		clock-names = "core_clk_src", "core_clk",
				"iface_clk", "bus_clk";
		qcom,ce-opp-freq = <100000000>;
		status = "ok";
	};

	qcom_tzlog: tz-log@8600720 {
		compatible = "qcom,tz-log";
		reg = <0x08600720 0x2000>;
		status = "ok";
	};

	emac0: qcom,emac@7c40000 {
		compatible = "qcom,mdm9607-emac";
		reg-names = "emac", "emac_csr", "emac_1588";
		reg = <0x7c40000 0x10000>,
			<0x7c56000 0x1000>,
			<0x7c5c000 0x4000>;

		#address-cells = <1>;
		#size-cells = <0>;
		interrupts-extended = <&intc 0 76 0>,
				      <&tlmm_pinmux 30 0x8>;
		interrupt-names = "emac_core0_irq", "emac_wol_irq";

		emac_vreg1-supply = <&mdm9607_l1>;
		emac_vreg2-supply = <&mdm9607_l3>;
		emac_vreg3-supply = <&mdm9607_l5>;
		emac_vreg4-supply = <&mdm9607_l11>;
		emac_vreg5-supply = <&emac_lan_vreg>;
		qcom,vdd-voltage-level = <1250000 1800000 2850000 1800000 0>;
		clocks = <&clock_gcc clk_gcc_emac_0_axi_clk>,
			 <&clock_gcc clk_gcc_emac_0_ahb_clk>,
			 <&clock_gcc clk_gcc_emac_0_125m_clk>,
			 <&clock_gcc clk_gcc_emac_0_sys_25m_clk>,
			 <&clock_gcc clk_gcc_emac_0_tx_clk>,
			 <&clock_gcc clk_gcc_emac_0_rx_clk>,
			 <&clock_gcc clk_gcc_emac_0_sys_clk>;
		clock-names = "axi_clk", "cfg_ahb_clk", "high_speed_clk",
			"mdio_clk", "tx_clk", "rx_clk", "sys_clk";

		internal-phy = <&emac_sgmii>;
		phy-handle = <&phy0>;
		phy-mode = "sgmii";

		pinctrl-names = "emac_mdio_active", "emac_mdio_sleep",
			"emac_ephy_active", "emac_ephy_sleep";
		pinctrl-0 = <&emac0_mdio_active>;
		pinctrl-1 = <&emac0_mdio_sleep>;
		pinctrl-2 = <&emac0_ephy_active>;
		pinctrl-3 = <&emac0_ephy_sleep>;
		qcom,emac-tstamp-en;
		qcom,emac-ptp-frac-ns-adj = <125000000 1>;

		qcom,msm-bus,name = "emac0";
		qcom,msm-bus,num-cases = <2>;
		qcom,msm-bus,num-paths = <1>;
		qcom,msm-bus,vectors-KBps =
				<114 512 0 0>,       /* No vote */
				<114 512 125000 800000>; /* Max. bandwidth */
		status = "disable";

		phy0: ethernet-phy@0 {
			reg = <0>;
		};
	};

	emac_sgmii: ethernet@7c58000 {
		compatible = "qcom,mdm9607-emac-sgmii";
		reg-names = "emac_sgmii";
		reg = <0x7c58000 0x400>;
		interrupt-names = "emac_sgmii_irq";
		interrupts = <0 80 0>;
	};

	pps {
		compatible = "pps-gpio";
		pinctrl-names = "default";
		pinctrl-0 = <&pinctrl_pps>;
		gpios = <&tlmm_pinmux 53 0>;
		status = "okay";
	};

	qcom,msm-dai-tdm-pri-rx {
		compatible = "qcom,msm-dai-tdm";
		qcom,msm-cpudai-tdm-group-id = <37120>;
		qcom,msm-cpudai-tdm-group-num-ports = <1>;
		qcom,msm-cpudai-tdm-group-port-id = <36864>;
		qcom,msm-cpudai-tdm-clk-rate = <12288000>;
		qcom,msm-cpudai-tdm-clk-attribute = /bits/ 16 <1>;
		dai_pri_tdm_rx_0: qcom,msm-dai-q6-tdm-pri-rx-0 {
			compatible = "qcom,msm-dai-q6-tdm";
			qcom,msm-cpudai-tdm-dev-id = <36864>;
			qcom,msm-cpudai-tdm-sync-mode = <0>;
			qcom,msm-cpudai-tdm-sync-src = <1>;
			qcom,msm-cpudai-tdm-data-out = <0>;
			qcom,msm-cpudai-tdm-invert-sync = <0>;
			qcom,msm-cpudai-tdm-data-delay = <1>;
			qcom,msm-cpudai-tdm-data-align = <0>;
		};
	};

	qcom,msm-dai-tdm-pri-tx {
		compatible = "qcom,msm-dai-tdm";
		qcom,msm-cpudai-tdm-group-id = <37121>;
		qcom,msm-cpudai-tdm-group-num-ports = <1>;
		qcom,msm-cpudai-tdm-group-port-id = <36865>;
		qcom,msm-cpudai-tdm-clk-rate = <12288000>;
		qcom,msm-cpudai-tdm-clk-attribute = /bits/ 16 <1>;
		dai_pri_tdm_tx_0: qcom,msm-dai-q6-tdm-pri-tx-0 {
			compatible = "qcom,msm-dai-q6-tdm";
			qcom,msm-cpudai-tdm-dev-id = <36865>;
			qcom,msm-cpudai-tdm-sync-mode = <0>;
			qcom,msm-cpudai-tdm-sync-src = <1>;
			qcom,msm-cpudai-tdm-data-out = <0>;
			qcom,msm-cpudai-tdm-invert-sync = <0>;
			qcom,msm-cpudai-tdm-data-delay = <1>;
			qcom,msm-cpudai-tdm-data-align = <0>;
		};
	};

	qcom,msm-dai-tdm-sec-rx {
		compatible = "qcom,msm-dai-tdm";
		qcom,msm-cpudai-tdm-group-id = <37136>;
		qcom,msm-cpudai-tdm-group-num-ports = <1>;
		qcom,msm-cpudai-tdm-group-port-id = <36880>;
		qcom,msm-cpudai-tdm-clk-rate = <12288000>;
		qcom,msm-cpudai-tdm-clk-attribute = /bits/ 16 <1>;
		dai_sec_tdm_rx_0: qcom,msm-dai-q6-tdm-sec-rx-0 {
			compatible = "qcom,msm-dai-q6-tdm";
			qcom,msm-cpudai-tdm-dev-id = <36880>;
			qcom,msm-cpudai-tdm-sync-mode = <0>;
			qcom,msm-cpudai-tdm-sync-src = <1>;
			qcom,msm-cpudai-tdm-data-out = <0>;
			qcom,msm-cpudai-tdm-invert-sync = <0>;
			qcom,msm-cpudai-tdm-data-delay = <1>;
			qcom,msm-cpudai-tdm-data-align = <0>;
		};
	};

	qcom,msm-dai-tdm-sec-tx {
		compatible = "qcom,msm-dai-tdm";
		qcom,msm-cpudai-tdm-group-id = <37137>;
		qcom,msm-cpudai-tdm-group-num-ports = <1>;
		qcom,msm-cpudai-tdm-group-port-id = <36881>;
		qcom,msm-cpudai-tdm-clk-rate = <12288000>;
		qcom,msm-cpudai-tdm-clk-attribute = /bits/ 16 <1>;
		dai_sec_tdm_tx_0: qcom,msm-dai-q6-tdm-sec-tx-0 {
			compatible = "qcom,msm-dai-q6-tdm";
			qcom,msm-cpudai-tdm-dev-id = <36881>;
			qcom,msm-cpudai-tdm-sync-mode = <0>;
			qcom,msm-cpudai-tdm-sync-src = <1>;
			qcom,msm-cpudai-tdm-data-out = <0>;
			qcom,msm-cpudai-tdm-invert-sync = <0>;
			qcom,msm-cpudai-tdm-data-delay = <1>;
			qcom,msm-cpudai-tdm-data-align = <0>;
		};
	};

	//add by max.tang for VBUS detect
	usb_detect {
		compatible = "qcom,gpio-usbdetect";
		interrupt-parent = <&spmi_bus>;
		interrupts = <0x0 0xA1 0x0>; /* PMD9607 MPP 2 */
		interrupt-names = "vbus_det_irq";
	};

	//2018-06-23,add by larry, for quectel low consume(Not Recommend)
	quec,quectel-low-consume-v2 {
		compatible = "quec,quectel-low-consume-v2";
		status = "ok";			/* ok by default */
	};

	quec,ql_lpm{
		compatible = "quec,ql_lpm";
		status = "ok";
	};
};

#include "pm8019-rpm-regulator.dtsi"
#include "pm8019.dtsi"


// #include "mdm9607-regulator.dtsi"

&rpm_bus {
	rpm-regulator-smpa2 {
		status = "okay";
		mdm9607_s2: regulator-s2 {
			compatible = "qcom,rpm-smd-regulator";
			regulator-name = "mdm9607_s2";
			regulator-min-microvolt = <750000>;
			regulator-max-microvolt = <1275000>;
			qcom,init-voltage = <750000>;
			status = "okay";
		};
	};

	/* CX supply */
	rpm-regulator-smpa3 {
		status = "okay";
		mdm9607_s3_level: regulator-s3-level {
			compatible = "qcom,rpm-smd-regulator";
			regulator-name = "mdm9607_s3_level";
			qcom,set = <3>;
			regulator-min-microvolt =
					<RPM_SMD_REGULATOR_LEVEL_RETENTION>;
			regulator-max-microvolt =
					<RPM_SMD_REGULATOR_LEVEL_TURBO_NO_CPR>;
			qcom,use-voltage-level;
		};

		mdm9607_s3_level_ao: regulator-s3-level-ao {
			compatible = "qcom,rpm-smd-regulator";
			regulator-name = "mdm9607_s3_level_ao";
			qcom,set = <1>;
			regulator-min-microvolt =
					<RPM_SMD_REGULATOR_LEVEL_RETENTION>;
			regulator-max-microvolt =
					<RPM_SMD_REGULATOR_LEVEL_TURBO_NO_CPR>;
			qcom,use-voltage-level;
		};

		mdm9607_s3_floor_level: regulator-s3-floor-level {
			compatible = "qcom,rpm-smd-regulator";
			regulator-name = "mdm9607_s3_floor_level";
			qcom,set = <3>;
			regulator-min-microvolt =
					<RPM_SMD_REGULATOR_LEVEL_RETENTION>;
			regulator-max-microvolt =
					<RPM_SMD_REGULATOR_LEVEL_TURBO_NO_CPR>;
			qcom,use-voltage-floor-level;
			qcom,always-send-voltage;
		};

		mdm9607_s3_level_so: regulator-s3-level-so {
			compatible = "qcom,rpm-smd-regulator";
			regulator-name = "mdm9607_s3_level_so";
			qcom,set = <2>;
			regulator-min-microvolt =
					<RPM_SMD_REGULATOR_LEVEL_RETENTION>;
			regulator-max-microvolt =
					<RPM_SMD_REGULATOR_LEVEL_TURBO_NO_CPR>;
			qcom,use-voltage-level;
		};
	};

	rpm-regulator-smpa4 {
		status = "okay";
		mdm9607_s4: regulator-s4 {
			compatible = "qcom,rpm-smd-regulator";
			regulator-name = "mdm9607_s4";
			regulator-min-microvolt = <1800000>;
			regulator-max-microvolt = <1950000>;
			qcom,init-voltage = <1800000>;
			status = "okay";
		};
	};

	rpm-regulator-ldoa1 {
		status = "okay";
		mdm9607_l1: regulator-l1 {
			compatible = "qcom,rpm-smd-regulator";
			regulator-name = "mdm9607_l1";
			regulator-min-microvolt = <1250000>;
			regulator-max-microvolt = <1250000>;
			qcom,init-voltage = <1250000>;
			status = "okay";
		};
	};

	rpm-regulator-ldoa2 {
		status = "okay";
		mdm9607_l2: regulator-l2 {
			compatible = "qcom,rpm-smd-regulator";
			regulator-name = "mdm9607_l2";
			regulator-min-microvolt = <1800000>;
			regulator-max-microvolt = <1800000>;
			qcom,init-voltage = <1800000>;
			status = "okay";
		};
	};

	rpm-regulator-ldoa3 {
		status = "okay";
		mdm9607_l3: regulator-l3 {
			compatible = "qcom,rpm-smd-regulator";
			regulator-name = "mdm9607_l3";
			regulator-min-microvolt = <1800000>;
			regulator-max-microvolt = <1800000>;
			qcom,init-voltage = <1800000>;
			status = "okay";
		};
	};

	rpm-regulator-ldoa4 {
		status = "okay";
		mdm9607_l4: regulator-l4 {
			compatible = "qcom,rpm-smd-regulator";
			regulator-name = "mdm9607_l4";
			regulator-min-microvolt = <3075000>;
			regulator-max-microvolt = <3075000>;
			qcom,init-voltage = <3075000>;
			status = "okay";
		};
	};

	rpm-regulator-ldoa5 {
		status = "okay";
		mdm9607_l5: regulator-l5 {
			compatible = "qcom,rpm-smd-regulator";
			regulator-name = "mdm9607_l5";
			regulator-min-microvolt = <1700000>;
			regulator-max-microvolt = <3050000>;
			qcom,init-voltage = <1700000>;
			status = "okay";
		};
	};

	rpm-regulator-ldoa6 {
		status = "okay";
		mdm9607_l6: regulator-l6 {
			compatible = "qcom,rpm-smd-regulator";
			regulator-name = "mdm9607_l6";
			regulator-min-microvolt = <1700000>;
			regulator-max-microvolt = <3050000>;
			qcom,init-voltage = <1700000>;
			status = "okay";
		};
	};

	rpm-regulator-ldoa7 {
		status = "okay";
		mdm9607_l7: regulator-l7 {
			compatible = "qcom,rpm-smd-regulator";
			regulator-name = "mdm9607_l7";
			regulator-min-microvolt = <1700000>;
			regulator-max-microvolt = <1900000>;
			qcom,init-voltage = <1700000>;
			status = "okay";
		};
	};

	rpm-regulator-ldoa8 {
		status = "okay";
		mdm9607_l8: regulator-l8 {
			compatible = "qcom,rpm-smd-regulator";
			regulator-name = "mdm9607_l8";
			regulator-min-microvolt = <1800000>;
			regulator-max-microvolt = <1800000>;
			qcom,init-voltage = <1800000>;
			status = "okay";
		};
	};

	rpm-regulator-ldoa9 {
		status = "okay";
		mdm9607_l9: regulator-l9 {
			compatible = "qcom,rpm-smd-regulator";
			regulator-name = "mdm9607_l9";
			regulator-min-microvolt = <1200000>;
			regulator-max-microvolt = <1250000>;
			qcom,init-voltage = <1200000>;
			status = "okay";
		};
	};

	rpm-regulator-ldoa10 {
		status = "okay";
		mdm9607_l10: regulator-l10 {
			compatible = "qcom,rpm-smd-regulator";
			regulator-name = "mdm9607_l10";
			regulator-min-microvolt = <1050000>;
			regulator-max-microvolt = <1050000>;
			qcom,init-voltage = <1050000>;
			status = "okay";
		};
	};

	rpm-regulator-ldoa11 {
		status = "okay";
		mdm9607_l11: regulator-l11 {
			compatible = "qcom,rpm-smd-regulator";
			regulator-name = "mdm9607_l11";
			regulator-min-microvolt = <1800000>;
			regulator-max-microvolt = <1800000>;
			qcom,init-voltage = <1800000>;
			status = "okay";
		};
	};

	/* MX supply */
	rpm-regulator-ldoa12 {
		status = "okay";
		mdm9607_l12_level: regulator-l12-level {
			compatible = "qcom,rpm-smd-regulator";
			regulator-name = "mdm9607_l12_level";
			qcom,set = <3>;
			regulator-min-microvolt =
					<RPM_SMD_REGULATOR_LEVEL_RETENTION>;
			regulator-max-microvolt =
					<RPM_SMD_REGULATOR_LEVEL_TURBO_NO_CPR>;
			qcom,use-voltage-level;
		};

		mdm9607_l12_level_ao: regulator-l12-level-ao {
			compatible = "qcom,rpm-smd-regulator";
			regulator-name = "mdm9607_l12_level_ao";
			qcom,set = <1>;
			regulator-min-microvolt =
					<RPM_SMD_REGULATOR_LEVEL_RETENTION>;
			regulator-max-microvolt =
					<RPM_SMD_REGULATOR_LEVEL_TURBO_NO_CPR>;
			qcom,use-voltage-level;
			qcom,always-send-voltage;
		};

		mdm9607_l12_level_so: regulator-l12-level-so {
			compatible = "qcom,rpm-smd-regulator";
			regulator-name = "mdm9607_l12_level_so";
			qcom,set = <2>;
			regulator-min-microvolt =
					<RPM_SMD_REGULATOR_LEVEL_RETENTION>;
			regulator-max-microvolt =
					<RPM_SMD_REGULATOR_LEVEL_TURBO_NO_CPR>;
			qcom,use-voltage-level;
		};

		mdm9607_l12_floor_level: regulator-l12-floor-level {
			compatible = "qcom,rpm-smd-regulator";
			regulator-name = "mdm9607_l12_floor_lebel";
			qcom,set = <3>;
			regulator-min-microvolt =
					<RPM_SMD_REGULATOR_LEVEL_RETENTION>;
			regulator-max-microvolt =
					<RPM_SMD_REGULATOR_LEVEL_TURBO_NO_CPR>;
			qcom,use-voltage-floor-level;
			qcom,always-send-voltage;
		};
	};

	rpm-regulator-ldoa13 {
		status = "okay";
		mdm9607_l13: regulator-l13 {
			compatible = "qcom,rpm-smd-regulator";
			regulator-name = "mdm9607_l13";
			regulator-min-microvolt = <1800000>;
			regulator-max-microvolt = <2850000>;
			qcom,init-voltage = <2850000>;
			status = "okay";
		};
	};

	rpm-regulator-ldoa14 {
		status = "okay";
		mdm9607_l14: regulator-l14 {
			compatible = "qcom,rpm-smd-regulator";
			regulator-name = "mdm9607_l14";
			regulator-min-microvolt = <2650000>;
			regulator-max-microvolt = <3000000>;
			qcom,init-voltage = <2650000>;
			status = "okay";
		};
	};
};

&spmi_bus {
	qcom,pm8019@1 {
		/* APC supply */
		mdm9607_s1: spm-regulator@1400 {
			compatible = "qcom,spm-regulator";
			reg = <0x1400 0x100>;
			regulator-name = "mdm9607_s1";
			regulator-min-microvolt = <1050000>;
			regulator-max-microvolt = <1350000>;
			qcom,bypass-spm; /* TODO: Remove once SPM is up */
		};
	};
};

&soc {
	mem_acc_vreg_corner: regulator@1942130 {
		compatible = "qcom,mem-acc-regulator";
		reg = <0x1942130 0x4>;
		reg-names = "acc-sel-l1";
		regulator-name = "mem_acc_corner";
		regulator-min-microvolt = <1>;
		regulator-max-microvolt = <3>;

		qcom,acc-sel-l1-bit-pos = <0>;
		qcom,corner-acc-map = <0 1 1>;
	};

	apc_vreg_corner: regulator@b018000 {
		compatible = "qcom,cpr-regulator";
		reg = <0xb018000 0x1000>, <0xb010058 4>, <0xa4000 0x1000>;
		reg-names = "rbcpr", "rbcpr_clk", "efuse_addr";
		interrupts = <0 20 0>;
		regulator-name = "apc_corner";
		qcom,cpr-fuse-corners = <3>;
		regulator-min-microvolt = <1>;
		regulator-max-microvolt = <7>;

		qcom,cpr-voltage-ceiling = <1050000 1225000 1350000>;
		qcom,cpr-voltage-floor = <1050000 1050000 1150000>;
		vdd-apc-supply = <&mdm9607_s1>;

		vdd-mx-supply = <&mdm9607_l12_level_ao>;
		qcom,vdd-mx-vmin-method = <4>;
		qcom,vdd-mx-corner-map = < RPM_SMD_REGULATOR_LEVEL_SVS
					   RPM_SMD_REGULATOR_LEVEL_NOM
					   RPM_SMD_REGULATOR_LEVEL_TURBO>;
		qcom,vdd-mx-vmax = <RPM_SMD_REGULATOR_LEVEL_TURBO_NO_CPR>;

		mem-acc-supply = <&mem_acc_vreg_corner>;

		qcom,cpr-ref-clk = <19200>;
		qcom,cpr-timer-delay = <5000>;
		qcom,cpr-timer-cons-up = <0>;
		qcom,cpr-timer-cons-down = <2>;
		qcom,cpr-irq-line = <0>;
		qcom,cpr-step-quotient = <22 0 24 0 0 0 0 0>;
		qcom,cpr-up-threshold = <2>;
		qcom,cpr-down-threshold = <3>;
		qcom,cpr-idle-clocks = <15>;
		qcom,cpr-gcnt-time = <1>;
		qcom,vdd-apc-step-up-limit = <1>;
		qcom,vdd-apc-step-down-limit = <1>;
		qcom,cpr-apc-volt-step = <12500>;

		qcom,cpr-fuse-row = <65 0>;
		qcom,cpr-fuse-target-quot = <24 12 0>;
		qcom,cpr-fuse-ro-sel = <42 39 36>;
		qcom,cpr-fuse-bp-cpr-disable = <54>;
		qcom,cpr-fuse-init-voltage =
					<66 6 6 0>,
					<66 0 6 0>,
					<65 45 6 0>;
		qcom,cpr-fuse-revision = <65 51 3 0>;
		qcom,cpr-init-voltage-ref = <1050000 1225000 1350000>;
		qcom,cpr-init-voltage-step = <10000>;
		qcom,cpr-corner-map = <1 2 3 3 3 3 3>;
		qcom,cpr-init-voltage-as-ceiling;
		qcom,cpr-corner-frequency-map =
					<1 400000000>,
					<2 800000000>,
					<3 998400000>,
					<4 1094400000>,
					<5 1190400000>,
					<6 1248000000>,
					<7 1305600000>;
		qcom,speed-bin-fuse-sel = <37 34 3 0>;
		qcom,cpr-speed-bin-max-corners =
					<0 0 1 2 7>;
		qcom,cpr-quot-adjust-scaling-factor-max = <1400>;
		qcom,disable-closed-loop-in-pc;
		qcom,cpr-cpus = <&CPU0>;
		qcom,cpr-enable;
	};

/* Miscellaneous regulators */
	sdcard_ext_vreg: sdcard_ext_vreg {
		compatible = "regulator-fixed";
		regulator-name = "sdcard_ext_vreg";
		startup-delay-us = <250>;
		enable-active-high;
		/* 20210225 bowen.gu statue led control */
		//gpio = <&pm8019_gpios 4 0>;
	};

	/* Rome 3.3V supply */
	rome_vreg: rome_vreg {
		compatible = "regulator-fixed";
		regulator-name = "rome_vreg";
		startup-delay-us = <4000>;
		enable-active-high;
		gpio = <&pm8019_gpios 3 0>;
	};

	emac_lan_vreg: emac_lan_vreg {
		compatible = "regulator-fixed";
		regulator-name = "emac_lan_vreg";
		startup-delay-us = <250>;
		enable-active-high;
		gpio = <&pm8019_mpps 1 0>;	////modified by gale 2016-08-22, mpp4 for adc function
	};
};

/* MPP pin 1 config for USB ID interrupt line */
&pm8019_mpps {
	mpp@a000 {
		qcom,mode = <0>;	/* Digital input */
		qcom,vin-sel = <3>;	/* 1.8V (L11) */
		qcom,src-sel = <0>;	/* QPNP_PIN_SEL_FUNC_CONSTANT */
		qcom,pull = <2>;	/* PULL UP 10KOHM */
		qcom,master-en = <1>;
		status = "okay";
	};
};

/*2016-01-22, comment out by jun.wu, smb358 is bot used
&usb_otg {
	vbus_otg-supply = <&smb358_otg_vreg>;
};
*/

&pm8019_vadc {
	chan@6 {
		label = "vbat_sns";
		reg = <6>;
		qcom,decimation = <0>;
		qcom,pre-div-channel-scaling = <1>;
		qcom,calibration-type = "absolute";
		qcom,scale-function = <0>;
		qcom,hw-settle-time = <0>;
		qcom,fast-avg-setup = <0>;
	};

	chan@7 {
		label = "vph_pwr";
		reg = <7>;
		qcom,decimation = <0>;
		qcom,pre-div-channel-scaling = <1>;
		qcom,calibration-type = "absolute";
		qcom,scale-function = <0>;
		qcom,hw-settle-time = <0>;
		qcom,fast-avg-setup = <0>;
	};

	/* Add by gale 2017-08-22, for adc0 function */
	chan@23 {
		label = "mpp4_vadc";
		reg = <0x23>; 				// channe0 for MPP4
		qcom,decimation = <0>;
		qcom,pre-div-channel-scaling = <1>; 	//Use 1:3 scaling to keep input
		qcom,calibration-type = "absolute";
		qcom,scale-function = <0>;
		qcom,hw-settle-time = <1>;
		qcom,fast-avg-setup = <2>;
	};
	
	/* Add by gale 2017-08-22, for adc1 function */
	chan@25 {
		label = "mpp6_vadc";
		reg = <0x25>;				// channe1 for MPP6
		qcom,decimation = <0>;
		qcom,pre-div-channel-scaling = <1>;	//Use 1:3 scaling to keep input
		qcom,calibration-type = "absolute";
		qcom,scale-function = <0>;
		qcom,hw-settle-time = <1>;
		qcom,fast-avg-setup = <2>;
	};

	chan@31 {
		label = "batt_id_therm";
		reg = <0x31>;
		qcom,decimation = <0>;
		qcom,pre-div-channel-scaling = <0>;
		qcom,calibration-type = "ratiometric";
		qcom,scale-function = <0>;
		qcom,hw-settle-time = <2>;
		qcom,fast-avg-setup = <0>;
	 };

	chan@33 {
		label = "pa_therm0";
		reg = <0x33>;
		qcom,decimation = <0>;
		qcom,pre-div-channel-scaling = <0>;
		qcom,calibration-type = "ratiometric";
		qcom,scale-function = <2>;
		qcom,hw-settle-time = <2>;
		qcom,fast-avg-setup = <0>;
	};
	//added by william 20201130, add ADC2 support
	chan@34 {
		label = "pa_therm1";
		reg = <0x34>;
		qcom,decimation = <0>;
		qcom,pre-div-channel-scaling = <0>;
		qcom,calibration-type = "absolute";
		qcom,scale-function = <0>;
		qcom,hw-settle-time = <1>;
		qcom,fast-avg-setup = <2>;
	};

	chan@32 {
		label = "xo_therm";
		reg = <0x32>;
		qcom,decimation = <0>;
		qcom,pre-div-channel-scaling = <0>;
		qcom,calibration-type = "ratiometric";
		qcom,scale-function = <4>;
		qcom,hw-settle-time = <2>;
		qcom,fast-avg-setup = <0>;
	};

	chan@3c {
		label = "xo_therm_amux";
		reg = <0x3c>;
		qcom,decimation = <0>;
		qcom,pre-div-channel-scaling = <0>;
		qcom,calibration-type = "ratiometric";
		qcom,scale-function = <4>;
		qcom,hw-settle-time = <2>;
		qcom,fast-avg-setup = <0>;
	};
};

&pm8019_adc_tm {
	/* Channel Node */
	chan@33 {
		label = "pa_therm0";
		reg = <0x33>;
		qcom,decimation = <0>;
		qcom,pre-div-channel-scaling = <0>;
		qcom,calibration-type = "ratiometric";
		qcom,scale-function = <2>;
		qcom,hw-settle-time = <2>;
		qcom,fast-avg-setup = <0>;
		qcom,btm-channel-number = <0x48>;
		qcom,thermal-node;
	};

	chan@34 {
		label = "pa_therm1";
		reg = <0x34>;
		qcom,decimation = <0>;
		qcom,pre-div-channel-scaling = <0>;
		qcom,calibration-type = "ratiometric";
		qcom,scale-function = <2>;
		qcom,hw-settle-time = <2>;
		qcom,fast-avg-setup = <0>;
		qcom,btm-channel-number = <0x68>;
		qcom,thermal-node;
	};
};
